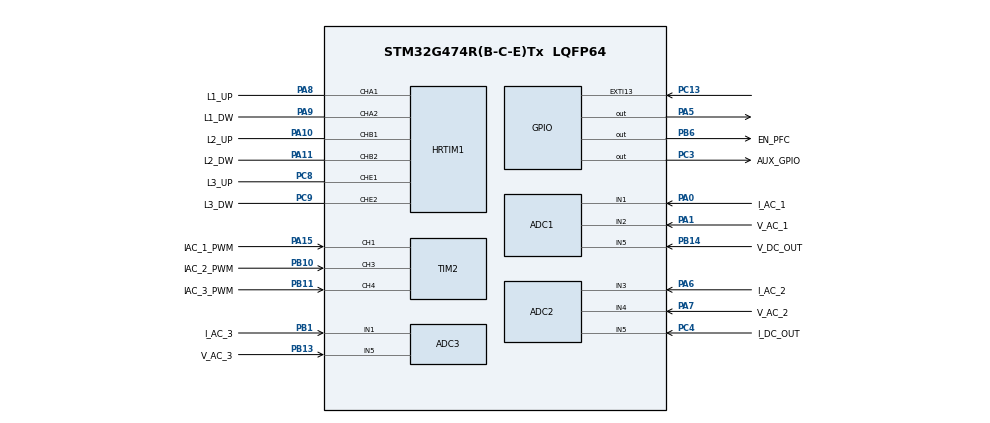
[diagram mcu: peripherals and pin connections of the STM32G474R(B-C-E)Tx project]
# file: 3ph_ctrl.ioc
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ADC1.Channel-0\#ChannelRegularConversion=ADC_CHANNEL_1
ADC1.Channel-1\#ChannelRegularConversion=ADC_CHANNEL_2
ADC1.Channel-2\#ChannelRegularConversion=ADC_CHANNEL_5
ADC1.ClockPrescaler=ADC_CLOCK_ASYNC_DIV6
ADC1.ContinuousConvMode=DISABLE
ADC1.DMAContinuousRequests=ENABLE
ADC1.EOCSelection=ADC_EOC_SEQ_CONV
ADC1.ExternalTrigConv=ADC_EXTERNALTRIG_T1_TRGO
ADC1.NbrOfConversion=3
ADC1.NbrOfConversionFlag=1
ADC1.OffsetNumber-0\#ChannelRegularConversion=ADC_OFFSET_NONE
ADC1.OffsetNumber-1\#ChannelRegularConversion=ADC_OFFSET_NONE
ADC1.OffsetNumber-2\#ChannelRegularConversion=ADC_OFFSET_NONE
ADC1.OversamplingMode=DISABLE
ADC1.Rank-0\#ChannelRegularConversion=1
ADC1.Rank-1\#ChannelRegularConversion=2
ADC1.Rank-2\#ChannelRegularConversion=3
ADC1.SamplingTime-0\#ChannelRegularConversion=ADC_SAMPLETIME_92CYCLES_5
ADC1.SamplingTime-1\#ChannelRegularConversion=ADC_SAMPLETIME_92CYCLES_5
ADC1.SamplingTime-2\#ChannelRegularConversion=ADC_SAMPLETIME_92CYCLES_5
ADC1.master=1
ADC2.Channel-0\#ChannelRegularConversion=ADC_CHANNEL_3
ADC2.Channel-1\#ChannelRegularConversion=ADC_CHANNEL_4
ADC2.Channel-2\#ChannelRegularConversion=ADC_CHANNEL_5
ADC2.ClockPrescaler=ADC_CLOCK_ASYNC_DIV6
ADC2.ContinuousConvMode=DISABLE
ADC2.DMAContinuousRequests=ENABLE
ADC2.EOCSelection=ADC_EOC_SEQ_CONV
ADC2.ExternalTrigConv=ADC_EXTERNALTRIG_T1_TRGO
ADC2.NbrOfConversion=3
ADC2.NbrOfConversionFlag=1
ADC2.OffsetNumber-0\#ChannelRegularConversion=ADC_OFFSET_NONE
ADC2.OffsetNumber-1\#ChannelRegularConversion=ADC_OFFSET_NONE
ADC2.OffsetNumber-2\#ChannelRegularConversion=ADC_OFFSET_NONE
ADC2.OversamplingMode=DISABLE
ADC2.Rank-0\#ChannelRegularConversion=1
ADC2.Rank-1\#ChannelRegularConversion=2
ADC2.Rank-2\#ChannelRegularConversion=3
ADC2.SamplingTime-0\#ChannelRegularConversion=ADC_SAMPLETIME_92CYCLES_5
ADC2.SamplingTime-1\#ChannelRegularConversion=ADC_SAMPLETIME_92CYCLES_5
ADC2.SamplingTime-2\#ChannelRegularConversion=ADC_SAMPLETIME_92CYCLES_5
ADC3.Channel-0\#ChannelRegularConversion=ADC_CHANNEL_1
ADC3.Channel-1\#ChannelRegularConversion=ADC_CHANNEL_5
ADC3.ClockPrescaler=ADC_CLOCK_ASYNC_DIV6
ADC3.ContinuousConvMode=DISABLE
ADC3.DMAContinuousRequests=ENABLE
ADC3.EOCSelection=ADC_EOC_SEQ_CONV
ADC3.ExternalTrigConv=ADC_EXTERNALTRIG_T1_TRGO
ADC3.NbrOfConversion=2
ADC3.NbrOfConversionFlag=1
ADC3.OffsetNumber-0\#ChannelRegularConversion=ADC_OFFSET_NONE
ADC3.OffsetNumber-1\#ChannelRegularConversion=ADC_OFFSET_NONE
ADC3.OversamplingMode=DISABLE
ADC3.Rank-0\#ChannelRegularConversion=1
ADC3.Rank-1\#ChannelRegularConversion=2
ADC3.SamplingTime-0\#ChannelRegularConversion=ADC_SAMPLETIME_92CYCLES_5
ADC3.SamplingTime-1\#ChannelRegularConversion=ADC_SAMPLETIME_92CYCLES_5
ADC3.master=1
Dma.ADC1.0.Direction=DMA_PERIPH_TO_MEMORY
Dma.ADC1.0.EventEnable=DISABLE
Dma.ADC1.0.Instance=DMA1_Channel1
Dma.ADC1.0.MemDataAlignment=DMA_MDATAALIGN_WORD
Dma.ADC1.0.MemInc=DMA_MINC_ENABLE
Dma.ADC1.0.Mode=DMA_CIRCULAR
Dma.ADC1.0.PeriphDataAlignment=DMA_PDATAALIGN_WORD
Dma.ADC1.0.PeriphInc=DMA_PINC_DISABLE
Dma.ADC1.0.Polarity=HAL_DMAMUX_REQ_GEN_RISING
Dma.ADC1.0.Priority=DMA_PRIORITY_HIGH
Dma.ADC1.0.RequestNumber=1
Dma.ADC1.0.SignalID=NONE
Dma.ADC1.0.SyncEnable=DISABLE
Dma.ADC1.0.SyncPolarity=HAL_DMAMUX_SYNC_NO_EVENT
Dma.ADC1.0.SyncRequestNumber=1
Dma.ADC1.0.SyncSignalID=NONE
Dma.ADC2.1.Direction=DMA_PERIPH_TO_MEMORY
Dma.ADC2.1.EventEnable=DISABLE
Dma.ADC2.1.Instance=DMA1_Channel2
Dma.ADC2.1.MemDataAlignment=DMA_MDATAALIGN_WORD
Dma.ADC2.1.MemInc=DMA_MINC_ENABLE
Dma.ADC2.1.Mode=DMA_CIRCULAR
Dma.ADC2.1.PeriphDataAlignment=DMA_PDATAALIGN_WORD
Dma.ADC2.1.PeriphInc=DMA_PINC_DISABLE
Dma.ADC2.1.Polarity=HAL_DMAMUX_REQ_GEN_RISING
Dma.ADC2.1.Priority=DMA_PRIORITY_HIGH
Dma.ADC2.1.RequestNumber=1
Dma.ADC2.1.SignalID=NONE
Dma.ADC2.1.SyncEnable=DISABLE
Dma.ADC2.1.SyncPolarity=HAL_DMAMUX_SYNC_NO_EVENT
Dma.ADC2.1.SyncRequestNumber=1
Dma.ADC2.1.SyncSignalID=NONE
Dma.ADC3.2.Direction=DMA_PERIPH_TO_MEMORY
Dma.ADC3.2.EventEnable=DISABLE
Dma.ADC3.2.Instance=DMA1_Channel3
Dma.ADC3.2.MemDataAlignment=DMA_MDATAALIGN_WORD
Dma.ADC3.2.MemInc=DMA_MINC_ENABLE
Dma.ADC3.2.Mode=DMA_CIRCULAR
Dma.ADC3.2.PeriphDataAlignment=DMA_PDATAALIGN_WORD
Dma.ADC3.2.PeriphInc=DMA_PINC_DISABLE
Dma.ADC3.2.Polarity=HAL_DMAMUX_REQ_GEN_RISING
Dma.ADC3.2.Priority=DMA_PRIORITY_HIGH
Dma.ADC3.2.RequestNumber=1
Dma.ADC3.2.SignalID=NONE
Dma.ADC3.2.SyncEnable=DISABLE
Dma.ADC3.2.SyncPolarity=HAL_DMAMUX_SYNC_NO_EVENT
Dma.ADC3.2.SyncRequestNumber=1
Dma.ADC3.2.SyncSignalID=NONE
Dma.Request0=ADC1
Dma.Request1=ADC2
Dma.Request2=ADC3
Dma.Request3=TIM2_CH1
Dma.Request4=TIM2_CH2
Dma.Request5=TIM2_CH3
Dma.Request6=TIM2_CH4
Dma.TIM2_CH1.3.Direction=DMA_PERIPH_TO_MEMORY
Dma.TIM2_CH1.3.EventEnable=DISABLE
Dma.TIM2_CH1.3.Instance=DMA1_Channel4
Dma.TIM2_CH1.3.MemDataAlignment=DMA_MDATAALIGN_WORD
Dma.TIM2_CH1.3.MemInc=DMA_MINC_ENABLE
Dma.TIM2_CH1.3.Mode=DMA_CIRCULAR
Dma.TIM2_CH1.3.PeriphDataAlignment=DMA_PDATAALIGN_WORD
Dma.TIM2_CH1.3.PeriphInc=DMA_PINC_DISABLE
Dma.TIM2_CH1.3.Polarity=HAL_DMAMUX_REQ_GEN_RISING
Dma.TIM2_CH1.3.Priority=DMA_PRIORITY_VERY_HIGH
Dma.TIM2_CH1.3.RequestNumber=1
Dma.TIM2_CH1.3.SignalID=NONE
Dma.TIM2_CH1.3.SyncEnable=DISABLE
Dma.TIM2_CH1.3.SyncPolarity=HAL_DMAMUX_SYNC_NO_EVENT
Dma.TIM2_CH1.3.SyncRequestNumber=1
Dma.TIM2_CH1.3.SyncSignalID=NONE
Dma.TIM2_CH2.4.Direction=DMA_PERIPH_TO_MEMORY
Dma.TIM2_CH2.4.EventEnable=DISABLE
Dma.TIM2_CH2.4.Instance=DMA1_Channel5
Dma.TIM2_CH2.4.MemDataAlignment=DMA_MDATAALIGN_WORD
Dma.TIM2_CH2.4.MemInc=DMA_MINC_ENABLE
Dma.TIM2_CH2.4.Mode=DMA_CIRCULAR
Dma.TIM2_CH2.4.PeriphDataAlignment=DMA_PDATAALIGN_WORD
Dma.TIM2_CH2.4.PeriphInc=DMA_PINC_DISABLE
Dma.TIM2_CH2.4.Polarity=HAL_DMAMUX_REQ_GEN_RISING
Dma.TIM2_CH2.4.Priority=DMA_PRIORITY_VERY_HIGH
Dma.TIM2_CH2.4.RequestNumber=1
Dma.TIM2_CH2.4.SignalID=NONE
Dma.TIM2_CH2.4.SyncEnable=DISABLE
Dma.TIM2_CH2.4.SyncPolarity=HAL_DMAMUX_SYNC_NO_EVENT
Dma.TIM2_CH2.4.SyncRequestNumber=1
Dma.TIM2_CH2.4.SyncSignalID=NONE
Dma.TIM2_CH3.5.Direction=DMA_PERIPH_TO_MEMORY
Dma.TIM2_CH3.5.EventEnable=DISABLE
Dma.TIM2_CH3.5.Instance=DMA1_Channel6
Dma.TIM2_CH3.5.MemDataAlignment=DMA_MDATAALIGN_WORD
Dma.TIM2_CH3.5.MemInc=DMA_MINC_ENABLE
Dma.TIM2_CH3.5.Mode=DMA_CIRCULAR
Dma.TIM2_CH3.5.PeriphDataAlignment=DMA_PDATAALIGN_WORD
Dma.TIM2_CH3.5.PeriphInc=DMA_PINC_DISABLE
Dma.TIM2_CH3.5.Polarity=HAL_DMAMUX_REQ_GEN_RISING
Dma.TIM2_CH3.5.Priority=DMA_PRIORITY_VERY_HIGH
Dma.TIM2_CH3.5.RequestNumber=1
Dma.TIM2_CH3.5.SignalID=NONE
Dma.TIM2_CH3.5.SyncEnable=DISABLE
Dma.TIM2_CH3.5.SyncPolarity=HAL_DMAMUX_SYNC_NO_EVENT
Dma.TIM2_CH3.5.SyncRequestNumber=1
Dma.TIM2_CH3.5.SyncSignalID=NONE
Dma.TIM2_CH4.6.Direction=DMA_PERIPH_TO_MEMORY
Dma.TIM2_CH4.6.EventEnable=DISABLE
Dma.TIM2_CH4.6.Instance=DMA1_Channel7
Dma.TIM2_CH4.6.MemDataAlignment=DMA_MDATAALIGN_WORD
Dma.TIM2_CH4.6.MemInc=DMA_MINC_ENABLE
Dma.TIM2_CH4.6.Mode=DMA_CIRCULAR
Dma.TIM2_CH4.6.PeriphDataAlignment=DMA_PDATAALIGN_WORD
Dma.TIM2_CH4.6.PeriphInc=DMA_PINC_DISABLE
Dma.TIM2_CH4.6.Polarity=HAL_DMAMUX_REQ_GEN_RISING
Dma.TIM2_CH4.6.Priority=DMA_PRIORITY_VERY_HIGH
Dma.TIM2_CH4.6.RequestNumber=1
Dma.TIM2_CH4.6.SignalID=NONE
Dma.TIM2_CH4.6.SyncEnable=DISABLE
Dma.TIM2_CH4.6.SyncPolarity=HAL_DMAMUX_SYNC_NO_EVENT
Dma.TIM2_CH4.6.SyncRequestNumber=1
Dma.TIM2_CH4.6.SyncSignalID=NONE
HRTIM1.CompareUnit1-MasterTimer=HRTIM_COMPAREUNIT_1
HRTIM1.CompareUnit1-Output_TA1TA2=HRTIM_COMPAREUNIT_1
HRTIM1.CompareUnit1-Output_TB1TB2=HRTIM_COMPAREUNIT_1
HRTIM1.CompareUnit1-Output_TE1TE2=HRTIM_COMPAREUNIT_1
HRTIM1.CompareValue1-Output_TA1TA2=30000
HRTIM1.CompareValue1-Output_TB1TB2=10000
HRTIM1.CompareValue1-Output_TE1TE2=20000
HRTIM1.DeadTimeInsertion-Output_TA1TA2=HRTIM_TIMDEADTIMEINSERTION_ENABLED
HRTIM1.DeadTimeInsertion-Output_TB1TB2=HRTIM_TIMDEADTIMEINSERTION_ENABLED
HRTIM1.DeadTimeInsertion-Output_TE1TE2=HRTIM_TIMDEADTIMEINSERTION_ENABLED
HRTIM1.FallingValue-Output_TA1TA2=274
HRTIM1.FallingValue-Output_TB1TB2=274
HRTIM1.FallingValue-Output_TE1TE2=320
HRTIM1.GreaterCMP1_TA=HRTIM_TIMERGTCMP1_GREATER
HRTIM1.GreaterCMP1_TB=HRTIM_TIMERGTCMP1_GREATER
HRTIM1.GreaterCMP1_TE=HRTIM_TIMERGTCMP1_GREATER
HRTIM1.NumberResetSource1-Output_TA1TA2=1
HRTIM1.NumberResetSource1-Output_TB1TB2=1
HRTIM1.NumberResetSource1-Output_TE1TE2=1
HRTIM1.NumberResetSource2_TA=1
HRTIM1.NumberResetTrigger-Output_TA1TA2=1
HRTIM1.NumberResetTrigger-Output_TB1TB2=1
HRTIM1.NumberResetTrigger-Output_TE1TE2=1
HRTIM1.NumberSetSource1-Output_TA1TA2=1
HRTIM1.NumberSetSource1-Output_TB1TB2=1
HRTIM1.NumberSetSource1-Output_TE1TE2=1
HRTIM1.NumberSetSource2_TA=1
HRTIM1.NumberUpdateTrigger-Output_TA1TA2=0
HRTIM1.NumberUpdateTrigger-Output_TB1TB2=1
HRTIM1.Periode_MASTER=41846
HRTIM1.Periode_TA=41846
HRTIM1.Periode_TB=41846
HRTIM1.Periode_TE=41846
HRTIM1.PreloadEnable-Output_TA1TA2=HRTIM_PRELOAD_ENABLED
HRTIM1.PreloadEnable-Output_TB1TB2=HRTIM_PRELOAD_ENABLED
HRTIM1.PreloadEnable-Output_TE1TE2=HRTIM_PRELOAD_ENABLED
HRTIM1.PrescalerRatio_MASTER=HRTIM_PRESCALERRATIO_MUL16
HRTIM1.PrescalerRatio_TA=HRTIM_PRESCALERRATIO_MUL32
HRTIM1.PrescalerRatio_TB=HRTIM_PRESCALERRATIO_MUL32
HRTIM1.PrescalerRatio_TE=HRTIM_PRESCALERRATIO_MUL32
HRTIM1.RepetitionUpdate-Output_TA1TA2=HRTIM_UPDATEONREPETITION_ENABLED
HRTIM1.RepetitionUpdate-Output_TB1TB2=HRTIM_UPDATEONREPETITION_ENABLED
HRTIM1.RepetitionUpdate-Output_TE1TE2=HRTIM_UPDATEONREPETITION_ENABLED
HRTIM1.ResetOutput1_Source1-Output_TA1TA2=HRTIM_OUTPUTRESET_TIMCMP1
HRTIM1.ResetOutput1_Source1-Output_TB1TB2=HRTIM_OUTPUTRESET_TIMCMP1
HRTIM1.ResetOutput1_Source1-Output_TE1TE2=HRTIM_OUTPUTRESET_TIMCMP1
HRTIM1.ResetOutput2_Source1-Output_TA1TA2=HRTIM_OUTPUTRESET_TIMCMP1
HRTIM1.ResetTrigger1-Output_TA1TA2=HRTIM_TIMRESETTRIGGER_MASTER_CMP1
HRTIM1.ResetTrigger1-Output_TB1TB2=HRTIM_TIMRESETTRIGGER_MASTER_CMP1
HRTIM1.ResetTrigger1-Output_TE1TE2=HRTIM_TIMRESETTRIGGER_MASTER_CMP1
HRTIM1.RisingValue-Output_TA1TA2=320
HRTIM1.RisingValue-Output_TB1TB2=320
HRTIM1.RisingValue-Output_TE1TE2=274
HRTIM1.SetOutput1_Source1-Output_TA1TA2=HRTIM_OUTPUTSET_TIMCMP1
HRTIM1.SetOutput1_Source1-Output_TB1TB2=HRTIM_OUTPUTSET_TIMCMP1
HRTIM1.SetOutput1_Source1-Output_TE1TE2=HRTIM_OUTPUTSET_TIMCMP1
HRTIM1.SetOutput2_Source1-Output_TA1TA2=HRTIM_OUTPUTSET_TIMCMP1
HRTIM1.UpDownMode-Output_TA1TA2=HRTIM_TIMERUPDOWNMODE_UPDOWN
HRTIM1.UpDownMode-Output_TB1TB2=HRTIM_TIMERUPDOWNMODE_UPDOWN
HRTIM1.UpDownMode-Output_TE1TE2=HRTIM_TIMERUPDOWNMODE_UPDOWN
HRTIM1.UpdateTrigger1-Output_TB1TB2=HRTIM_TIMUPDATETRIGGER_MASTER
Mcu.Family=STM32G4
Mcu.Name=STM32G474R(B-C-E)Tx
Mcu.Package=LQFP64
NUCLEO-G474RE.BUTTON=1
NUCLEO-G474RE.LD2=true
NUCLEO-G474RE.VCP=true
NVIC.DMA1_Channel1_IRQn=true\:0\:0\:false\:false\:true\:false\:true\:true
NVIC.DMA1_Channel2_IRQn=true\:0\:0\:false\:false\:true\:false\:true\:true
NVIC.DMA1_Channel3_IRQn=true\:0\:0\:false\:false\:true\:false\:true\:true
NVIC.DMA1_Channel4_IRQn=true\:0\:0\:false\:false\:true\:false\:true\:true
NVIC.DMA1_Channel5_IRQn=true\:0\:0\:false\:false\:true\:false\:true\:true
NVIC.DMA1_Channel6_IRQn=true\:0\:0\:false\:false\:true\:false\:true\:true
NVIC.DMA1_Channel7_IRQn=true\:0\:0\:false\:false\:true\:false\:true\:true
NVIC.EXTI15_10_IRQn=true\:0\:0\:false\:false\:true\:true\:true\:true
NVIC.PriorityGroup=NVIC_PRIORITYGROUP_4
NVIC.TIM1_UP_TIM16_IRQn=true\:0\:0\:false\:false\:true\:true\:true\:true
PA0.GPIO_Label=I_AC_1
PA0.Mode=IN1-Single-Ended
PA0.Signal=ADC1_IN1
PA1.GPIO_Label=V_AC_1
PA1.Mode=IN2-Single-Ended
PA1.Signal=ADC1_IN2
PA10.GPIO_Label=L2_UP
PA10.Mode=Output_TB1TB2
PA10.Signal=HRTIM1_CHB1
PA11.GPIO_Label=L2_DW
PA11.Mode=Output_TB1TB2
PA11.Signal=HRTIM1_CHB2
PA13.GPIO_Label=T_SWDIO
PA13.Signal=SYS_JTMS-SWDIO
PA14.GPIO_Label=T_SWCLK
PA14.Signal=SYS_JTCK-SWCLK
PA15.GPIO_Label=IAC_1_PWM
PA15.GPIO_Speed=GPIO_SPEED_FREQ_HIGH
PA15.Signal=S_TIM2_CH1
PA2.Signal=LPUART1_TX
PA3.Signal=LPUART1_RX
PA5.Signal=GPIO_Output
PA6.GPIO_Label=I_AC_2
PA6.Mode=IN3-Single-Ended
PA6.Signal=ADC2_IN3
PA7.GPIO_Label=V_AC_2
PA7.Mode=IN4-Single-Ended
PA7.Signal=ADC2_IN4
PA8.GPIO_Label=L1_UP
PA8.Mode=Output_TA1TA2
PA8.Signal=HRTIM1_CHA1
PA9.GPIO_Label=L1_DW
PA9.Mode=Output_TA1TA2
PA9.Signal=HRTIM1_CHA2
PB1.GPIO_Label=I_AC_3
PB1.Mode=IN1-Single-Ended
PB1.Signal=ADC3_IN1
PB10.GPIO_Label=IAC_2_PWM
PB10.GPIO_Speed=GPIO_SPEED_FREQ_HIGH
PB10.Signal=S_TIM2_CH3
PB11.GPIO_Label=IAC_3_PWM
PB11.GPIO_Speed=GPIO_SPEED_FREQ_HIGH
PB11.Signal=S_TIM2_CH4
PB13.GPIO_Label=V_AC_3
PB13.Mode=IN5-Single-Ended
PB13.Signal=ADC3_IN5
PB14.GPIO_Label=V_DC_OUT
PB14.Mode=IN5-Single-Ended
PB14.Signal=ADC1_IN5
PB3.GPIO_Label=T_SWO
PB3.Signal=SYS_JTDO-SWO
PB6.GPIO_Label=EN_PFC
PB6.Signal=GPIO_Output
PC13.Signal=GPXTI13
PC14-OSC32_IN.GPIO_Label=RCC_OSC32_IN
PC14-OSC32_IN.Signal=RCC_OSC32_IN
PC15-OSC32_OUT.GPIO_Label=RCC_OSC32_OUT
PC15-OSC32_OUT.Signal=RCC_OSC32_OUT
PC3.GPIO_Label=AUX_GPIO
PC3.GPIO_Speed=GPIO_SPEED_FREQ_VERY_HIGH
PC3.Signal=GPIO_Output
PC4.GPIO_Label=I_DC_OUT
PC4.Mode=IN5-Single-Ended
PC4.Signal=ADC2_IN5
PC8.GPIO_Label=L3_UP
PC8.Mode=Output_TE1TE2
PC8.Signal=HRTIM1_CHE1
PC9.GPIO_Label=L3_DW
PC9.Mode=Output_TE1TE2
PC9.Signal=HRTIM1_CHE2
PF0-OSC_IN.GPIO_Label=RCC_OSC_IN
PF0-OSC_IN.Signal=RCC_OSC_IN
PF1-OSC_OUT.GPIO_Label=RCC_OSC_OUT
PF1-OSC_OUT.Signal=RCC_OSC_OUT
ProjectManager.HeapSize=0x200
ProjectManager.StackSize=0x400
ProjectManager.TargetToolchain=CMake
RCC.ADC12Freq_Value=170000000
RCC.ADC345Freq_Value=170000000
RCC.AHBFreq_Value=170000000
RCC.APB1Freq_Value=170000000
RCC.APB1TimFreq_Value=170000000
RCC.APB2Freq_Value=170000000
RCC.APB2TimFreq_Value=170000000
RCC.CortexFreq_Value=170000000
RCC.EXTERNAL_CLOCK_VALUE=12288000
RCC.HCLKFreq_Value=170000000
RCC.HSE_VALUE=24000000
RCC.HSI48_VALUE=48000000
RCC.HSI_VALUE=16000000
RCC.LSE_VALUE=32768
RCC.PLLM=RCC_PLLM_DIV4
RCC.PLLN=85
RCC.RTCClockSelection=RCC_RTCCLKSOURCE_LSE
RCC.SYSCLKFreq_VALUE=170000000
RCC.SYSCLKSource=RCC_SYSCLKSOURCE_PLLCLK
RCC.USBFreq_Value=170000000
RCC.VCOOutputFreq_Value=340000000
SH.S_TIM2_CH1.0=TIM2_CH1,Input_Capture1_from_TI1
SH.S_TIM2_CH1.1=TIM2_CH1,TriggerSource_TI1FP1
SH.S_TIM2_CH3.0=TIM2_CH3,Input_Capture3_from_TI3
SH.S_TIM2_CH4.0=TIM2_CH4,Input_Capture4_from_TI4
TIM1.PeriodNoDither=21250
TIM1.TIM_MasterOutputTrigger=TIM_TRGO_UPDATE
TIM1.TIM_MasterOutputTrigger2=TIM_TRGO2_UPDATE
TIM1.TIM_MasterSlaveMode=TIM_MASTERSLAVEMODE_DISABLE
TIM2.Channel-Input_Capture1_from_TI1=TIM_CHANNEL_1
TIM2.Channel-Input_Capture2_from_TI1_63=TIM_CHANNEL_2
TIM2.Channel-Input_Capture3_from_TI3=TIM_CHANNEL_3
TIM2.Channel-Input_Capture4_from_TI4=TIM_CHANNEL_4
TIM2.ICFilter_CH1=10
TIM2.ICFilter_CH3=10
TIM2.ICFilter_CH4=10
TIM2.ICPolarity_CH2=TIM_INPUTCHANNELPOLARITY_FALLING
TIM2.ICPolarity_CH3=TIM_INPUTCHANNELPOLARITY_FALLING
TIM2.ICPolarity_CH4=TIM_INPUTCHANNELPOLARITY_FALLING
VP_FMAC_VS_FMAC.Mode=FMAC_Activate
VP_HRTIM1_VS_hrtimMasterTimerNoOutput.Mode=MasterTimer
VP_NUCLEO-G474RE_VS_BSP_COMMON.Mode=COMMON
VP_SYS_VS_DBSignals.Mode=DisableDeadBatterySignals
VP_TIM1_VS_ClockSourceINT.Mode=Internal
VP_TIM2_VS_ClockSourceINT.Mode=Internal
VP_TIM2_VS_ControllerModeReset.Mode=Reset Mode
VP_TIM2_VS_indirect_ch1.Mode=Input_Capture2_from_TI1_63
board=NUCLEO-G474RE

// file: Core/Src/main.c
/* USER CODE BEGIN Header */
/**
 ******************************************************************************
 * @file           : main.c
 * @brief          : Main program body
 ******************************************************************************
 * @attention
 *
 * Copyright (c) 2025 STMicroelectronics.
 * All rights reserved.
 *
 * This software is licensed under terms that can be found in the LICENSE file
 * in the root directory of this software component.
 * If no LICENSE file comes with this software, it is provided AS-IS.
 *
 ******************************************************************************
 */
/* USER CODE END Header */
#include "main.h"

/* USER CODE BEGIN PD */
uint32_t adc1_data[18], adc2_data[18], adc3_data[12], i_ac[4];

/* USER CODE END PD */

COM_InitTypeDef BspCOMInit;

void SystemClock_Config(void);
static void MX_GPIO_Init(void);
static void MX_DMA_Init(void);
static void MX_ADC1_Init(void);
static void MX_ADC2_Init(void);
static void MX_ADC3_Init(void);
static void MX_FMAC_Init(void);
static void MX_TIM1_Init(void);
static void MX_HRTIM1_Init(void);
static void MX_TIM2_Init(void);

int main(void)
{

  /* MCU Configuration--------------------------------------------------------*/

  /* Reset of all peripherals, Initializes the Flash interface and the Systick. */
  HAL_Init();

  /* Configure the system clock */
  SystemClock_Config();

  /* Initialize all configured peripherals */
  MX_GPIO_Init();
  MX_DMA_Init();
  MX_ADC1_Init();
  MX_ADC2_Init();
  MX_ADC3_Init();
  MX_FMAC_Init();
  MX_TIM1_Init();
  MX_HRTIM1_Init();
  MX_TIM2_Init();

  /* Initialize led */
  BSP_LED_Init(LED_GREEN);

  /* Initialize USER push-button, will be used to trigger an interrupt each time it's pressed.*/
  BSP_PB_Init(BUTTON_USER, BUTTON_MODE_EXTI);

  /* Initialize COM1 port (115200, 8 bits (7-bit data + 1 stop bit), no parity */
  BspCOMInit.BaudRate   = 115200;
  BspCOMInit.WordLength = COM_WORDLENGTH_8B;
  BspCOMInit.StopBits   = COM_STOPBITS_1;
  BspCOMInit.Parity     = COM_PARITY_NONE;
  BspCOMInit.HwFlowCtl  = COM_HWCONTROL_NONE;
  if (BSP_COM_Init(COM1, &BspCOMInit) != BSP_ERROR_NONE)
  {
    Error_Handler();
  }

  /* Infinite loop */
  /* USER CODE BEGIN WHILE */
  __disable_irq();

  LL_ADC_ClearFlag_OVR(ADC1);
  LL_ADC_ClearFlag_OVR(ADC2);
  LL_ADC_ClearFlag_OVR(ADC3);
  LL_ADC_Enable(ADC1);
  LL_ADC_Enable(ADC2);
  LL_ADC_Enable(ADC3);
  LL_ADC_REG_StartConversion(ADC1);
  LL_ADC_REG_StartConversion(ADC2);
  LL_ADC_REG_StartConversion(ADC3);
  LL_TIM_CC_EnableChannel(TIM2, LL_TIM_CHANNEL_CH1);
  LL_TIM_CC_EnableChannel(TIM2, LL_TIM_CHANNEL_CH2);
  LL_TIM_CC_EnableChannel(TIM2, LL_TIM_CHANNEL_CH3);
  LL_TIM_CC_EnableChannel(TIM2, LL_TIM_CHANNEL_CH4);
  LL_TIM_EnableCounter(TIM2);
  /*HRTIM*/

  __enable_irq();
  while (1) {

    /* USER CODE END WHILE */

  }
}

void SystemClock_Config(void)
{
  LL_FLASH_SetLatency(LL_FLASH_LATENCY_4);
  while(LL_FLASH_GetLatency() != LL_FLASH_LATENCY_4)
  {
  }
  LL_PWR_EnableRange1BoostMode();
  LL_RCC_HSI_Enable();
   /* Wait till HSI is ready */
  while(LL_RCC_HSI_IsReady() != 1)
  {
  }

  LL_RCC_HSI_SetCalibTrimming(64);
  LL_RCC_PLL_ConfigDomain_SYS(LL_RCC_PLLSOURCE_HSI, LL_RCC_PLLM_DIV_4, 85, LL_RCC_PLLR_DIV_2);
  LL_RCC_PLL_EnableDomain_SYS();
  LL_RCC_PLL_Enable();
   /* Wait till PLL is ready */
  while(LL_RCC_PLL_IsReady() != 1)
  {
  }

  LL_RCC_SetSysClkSource(LL_RCC_SYS_CLKSOURCE_PLL);
  LL_RCC_SetAHBPrescaler(LL_RCC_SYSCLK_DIV_2);
   /* Wait till System clock is ready */
  while(LL_RCC_GetSysClkSource() != LL_RCC_SYS_CLKSOURCE_STATUS_PLL)
  {
  }

  /* Insure 1us transition state at intermediate medium speed clock*/
  for (__IO uint32_t i = (170 >> 1); i !=0; i--);

  /* Set AHB prescaler*/
  LL_RCC_SetAHBPrescaler(LL_RCC_SYSCLK_DIV_1);
  LL_RCC_SetAPB1Prescaler(LL_RCC_APB1_DIV_1);
  LL_RCC_SetAPB2Prescaler(LL_RCC_APB2_DIV_1);
  LL_SetSystemCoreClock(170000000);

   /* Update the time base */
  if (HAL_InitTick (TICK_INT_PRIORITY) != HAL_OK)
  {
    Error_Handler();
  }
}

static void MX_ADC1_Init(void)
{

  LL_ADC_InitTypeDef ADC_InitStruct = {0};
  LL_ADC_REG_InitTypeDef ADC_REG_InitStruct = {0};
  LL_ADC_CommonInitTypeDef ADC_CommonInitStruct = {0};

  LL_GPIO_InitTypeDef GPIO_InitStruct = {0};

  LL_RCC_SetADCClockSource(LL_RCC_ADC12_CLKSOURCE_SYSCLK);

  /* Peripheral clock enable */
  LL_AHB2_GRP1_EnableClock(LL_AHB2_GRP1_PERIPH_ADC12);

  LL_AHB2_GRP1_EnableClock(LL_AHB2_GRP1_PERIPH_GPIOA);
  LL_AHB2_GRP1_EnableClock(LL_AHB2_GRP1_PERIPH_GPIOB);
  /**ADC1 GPIO Configuration
  PA0   ------> ADC1_IN1
  PA1   ------> ADC1_IN2
  PB14   ------> ADC1_IN5
  */
  GPIO_InitStruct.Pin = I_AC_1_Pin;
  GPIO_InitStruct.Mode = LL_GPIO_MODE_ANALOG;
  GPIO_InitStruct.Pull = LL_GPIO_PULL_NO;
  LL_GPIO_Init(I_AC_1_GPIO_Port, &GPIO_InitStruct);

  GPIO_InitStruct.Pin = V_AC_1_Pin;
  GPIO_InitStruct.Mode = LL_GPIO_MODE_ANALOG;
  GPIO_InitStruct.Pull = LL_GPIO_PULL_NO;
  LL_GPIO_Init(V_AC_1_GPIO_Port, &GPIO_InitStruct);

  GPIO_InitStruct.Pin = V_DC_OUT_Pin;
  GPIO_InitStruct.Mode = LL_GPIO_MODE_ANALOG;
  GPIO_InitStruct.Pull = LL_GPIO_PULL_NO;
  LL_GPIO_Init(V_DC_OUT_GPIO_Port, &GPIO_InitStruct);

  /* ADC1 DMA Init */

  /* ADC1 Init */
  LL_DMA_SetPeriphRequest(DMA1, LL_DMA_CHANNEL_1, LL_DMAMUX_REQ_ADC1);

  LL_DMA_SetDataTransferDirection(DMA1, LL_DMA_CHANNEL_1, LL_DMA_DIRECTION_PERIPH_TO_MEMORY);

  LL_DMA_SetChannelPriorityLevel(DMA1, LL_DMA_CHANNEL_1, LL_DMA_PRIORITY_HIGH);

  LL_DMA_SetMode(DMA1, LL_DMA_CHANNEL_1, LL_DMA_MODE_CIRCULAR);

  LL_DMA_SetPeriphIncMode(DMA1, LL_DMA_CHANNEL_1, LL_DMA_PERIPH_NOINCREMENT);

  LL_DMA_SetMemoryIncMode(DMA1, LL_DMA_CHANNEL_1, LL_DMA_MEMORY_INCREMENT);

  LL_DMA_SetPeriphSize(DMA1, LL_DMA_CHANNEL_1, LL_DMA_PDATAALIGN_WORD);

  LL_DMA_SetMemorySize(DMA1, LL_DMA_CHANNEL_1, LL_DMA_MDATAALIGN_WORD);

  /** Common config
  */
  ADC_InitStruct.Resolution = LL_ADC_RESOLUTION_12B;
  ADC_InitStruct.DataAlignment = LL_ADC_DATA_ALIGN_RIGHT;
  ADC_InitStruct.LowPowerMode = LL_ADC_LP_MODE_NONE;
  LL_ADC_Init(ADC1, &ADC_InitStruct);
  ADC_REG_InitStruct.TriggerSource = LL_ADC_REG_TRIG_EXT_TIM1_TRGO;
  ADC_REG_InitStruct.SequencerLength = LL_ADC_REG_SEQ_SCAN_ENABLE_3RANKS;
  ADC_REG_InitStruct.SequencerDiscont = LL_ADC_REG_SEQ_DISCONT_DISABLE;
  ADC_REG_InitStruct.ContinuousMode = LL_ADC_REG_CONV_SINGLE;
  ADC_REG_InitStruct.DMATransfer = LL_ADC_REG_DMA_TRANSFER_UNLIMITED;
  ADC_REG_InitStruct.Overrun = LL_ADC_REG_OVR_DATA_PRESERVED;
  LL_ADC_REG_Init(ADC1, &ADC_REG_InitStruct);
  LL_ADC_SetGainCompensation(ADC1, 0);
  LL_ADC_SetOverSamplingScope(ADC1, LL_ADC_OVS_DISABLE);
  ADC_CommonInitStruct.CommonClock = LL_ADC_CLOCK_ASYNC_DIV6;
  ADC_CommonInitStruct.Multimode = LL_ADC_MULTI_INDEPENDENT;
  LL_ADC_CommonInit(__LL_ADC_COMMON_INSTANCE(ADC1), &ADC_CommonInitStruct);
  LL_ADC_REG_SetTriggerEdge(ADC1, LL_ADC_REG_TRIG_EXT_RISING);

  /* Disable ADC deep power down (enabled by default after reset state) */
  LL_ADC_DisableDeepPowerDown(ADC1);
  /* Enable ADC internal voltage regulator */
  LL_ADC_EnableInternalRegulator(ADC1);
  /* Delay for ADC internal voltage regulator stabilization. */
  /* Compute number of CPU cycles to wait for, from delay in us. */
  /* Note: Variable divided by 2 to compensate partially */
  /* CPU processing cycles (depends on compilation optimization). */
  /* Note: If system core clock frequency is below 200kHz, wait time */
  /* is only a few CPU processing cycles. */
  uint32_t wait_loop_index;
  wait_loop_index = ((LL_ADC_DELAY_INTERNAL_REGUL_STAB_US * (SystemCoreClock / (100000 * 2))) / 10);
  while(wait_loop_index != 0)
  {
    wait_loop_index--;
  }

  /** Configure Regular Channel
  */
  LL_ADC_REG_SetSequencerRanks(ADC1, LL_ADC_REG_RANK_1, LL_ADC_CHANNEL_1);
  LL_ADC_SetChannelSamplingTime(ADC1, LL_ADC_CHANNEL_1, LL_ADC_SAMPLINGTIME_92CYCLES_5);
  LL_ADC_SetChannelSingleDiff(ADC1, LL_ADC_CHANNEL_1, LL_ADC_SINGLE_ENDED);

  /** Configure Regular Channel
  */
  LL_ADC_REG_SetSequencerRanks(ADC1, LL_ADC_REG_RANK_2, LL_ADC_CHANNEL_2);
  LL_ADC_SetChannelSamplingTime(ADC1, LL_ADC_CHANNEL_2, LL_ADC_SAMPLINGTIME_92CYCLES_5);
  LL_ADC_SetChannelSingleDiff(ADC1, LL_ADC_CHANNEL_2, LL_ADC_SINGLE_ENDED);

  /** Configure Regular Channel
  */
  LL_ADC_REG_SetSequencerRanks(ADC1, LL_ADC_REG_RANK_3, LL_ADC_CHANNEL_5);
  LL_ADC_SetChannelSamplingTime(ADC1, LL_ADC_CHANNEL_5, LL_ADC_SAMPLINGTIME_92CYCLES_5);
  LL_ADC_SetChannelSingleDiff(ADC1, LL_ADC_CHANNEL_5, LL_ADC_SINGLE_ENDED);
  /* USER CODE BEGIN ADC1_Init 2 */
  LL_DMA_ConfigAddresses(
      DMA1, LL_DMA_CHANNEL_1,
      LL_ADC_DMA_GetRegAddr(ADC1, LL_ADC_DMA_REG_REGULAR_DATA),
      (uint32_t)&adc1_data[0], LL_DMA_DIRECTION_PERIPH_TO_MEMORY);
  LL_DMA_SetDataLength(DMA1, LL_DMA_CHANNEL_1, (uint32_t)NUM_TAPS * 3);
  // LL_DMA_EnableIT_TC(DMA1, LL_DMA_CHANNEL_1);
  LL_DMA_EnableChannel(DMA1, LL_DMA_CHANNEL_1);
  /* USER CODE END ADC1_Init 2 */

}

static void MX_ADC2_Init(void)
{

  LL_ADC_InitTypeDef ADC_InitStruct = {0};
  LL_ADC_REG_InitTypeDef ADC_REG_InitStruct = {0};

  LL_GPIO_InitTypeDef GPIO_InitStruct = {0};

  LL_RCC_SetADCClockSource(LL_RCC_ADC12_CLKSOURCE_SYSCLK);

  /* Peripheral clock enable */
  LL_AHB2_GRP1_EnableClock(LL_AHB2_GRP1_PERIPH_ADC12);

  LL_AHB2_GRP1_EnableClock(LL_AHB2_GRP1_PERIPH_GPIOA);
  LL_AHB2_GRP1_EnableClock(LL_AHB2_GRP1_PERIPH_GPIOC);
  /**ADC2 GPIO Configuration
  PA6   ------> ADC2_IN3
  PA7   ------> ADC2_IN4
  PC4   ------> ADC2_IN5
  */
  GPIO_InitStruct.Pin = I_AC_2_Pin;
  GPIO_InitStruct.Mode = LL_GPIO_MODE_ANALOG;
  GPIO_InitStruct.Pull = LL_GPIO_PULL_NO;
  LL_GPIO_Init(I_AC_2_GPIO_Port, &GPIO_InitStruct);

  GPIO_InitStruct.Pin = V_AC_2_Pin;
  GPIO_InitStruct.Mode = LL_GPIO_MODE_ANALOG;
  GPIO_InitStruct.Pull = LL_GPIO_PULL_NO;
  LL_GPIO_Init(V_AC_2_GPIO_Port, &GPIO_InitStruct);

  GPIO_InitStruct.Pin = I_DC_OUT_Pin;
  GPIO_InitStruct.Mode = LL_GPIO_MODE_ANALOG;
  GPIO_InitStruct.Pull = LL_GPIO_PULL_NO;
  LL_GPIO_Init(I_DC_OUT_GPIO_Port, &GPIO_InitStruct);

  /* ADC2 DMA Init */

  /* ADC2 Init */
  LL_DMA_SetPeriphRequest(DMA1, LL_DMA_CHANNEL_2, LL_DMAMUX_REQ_ADC2);

  LL_DMA_SetDataTransferDirection(DMA1, LL_DMA_CHANNEL_2, LL_DMA_DIRECTION_PERIPH_TO_MEMORY);

  LL_DMA_SetChannelPriorityLevel(DMA1, LL_DMA_CHANNEL_2, LL_DMA_PRIORITY_HIGH);

  LL_DMA_SetMode(DMA1, LL_DMA_CHANNEL_2, LL_DMA_MODE_CIRCULAR);

  LL_DMA_SetPeriphIncMode(DMA1, LL_DMA_CHANNEL_2, LL_DMA_PERIPH_NOINCREMENT);

  LL_DMA_SetMemoryIncMode(DMA1, LL_DMA_CHANNEL_2, LL_DMA_MEMORY_INCREMENT);

  LL_DMA_SetPeriphSize(DMA1, LL_DMA_CHANNEL_2, LL_DMA_PDATAALIGN_WORD);

  LL_DMA_SetMemorySize(DMA1, LL_DMA_CHANNEL_2, LL_DMA_MDATAALIGN_WORD);

  /** Common config
  */
  ADC_InitStruct.Resolution = LL_ADC_RESOLUTION_12B;
  ADC_InitStruct.DataAlignment = LL_ADC_DATA_ALIGN_RIGHT;
  ADC_InitStruct.LowPowerMode = LL_ADC_LP_MODE_NONE;
  LL_ADC_Init(ADC2, &ADC_InitStruct);
  ADC_REG_InitStruct.TriggerSource = LL_ADC_REG_TRIG_EXT_TIM1_TRGO;
  ADC_REG_InitStruct.SequencerLength = LL_ADC_REG_SEQ_SCAN_ENABLE_3RANKS;
  ADC_REG_InitStruct.SequencerDiscont = LL_ADC_REG_SEQ_DISCONT_DISABLE;
  ADC_REG_InitStruct.ContinuousMode = LL_ADC_REG_CONV_SINGLE;
  ADC_REG_InitStruct.DMATransfer = LL_ADC_REG_DMA_TRANSFER_UNLIMITED;
  ADC_REG_InitStruct.Overrun = LL_ADC_REG_OVR_DATA_PRESERVED;
  LL_ADC_REG_Init(ADC2, &ADC_REG_InitStruct);
  LL_ADC_SetGainCompensation(ADC2, 0);
  LL_ADC_SetOverSamplingScope(ADC2, LL_ADC_OVS_DISABLE);
  LL_ADC_REG_SetTriggerEdge(ADC2, LL_ADC_REG_TRIG_EXT_RISING);

  /* Disable ADC deep power down (enabled by default after reset state) */
  LL_ADC_DisableDeepPowerDown(ADC2);
  /* Enable ADC internal voltage regulator */
  LL_ADC_EnableInternalRegulator(ADC2);
  /* Delay for ADC internal voltage regulator stabilization. */
  /* Compute number of CPU cycles to wait for, from delay in us. */
  /* Note: Variable divided by 2 to compensate partially */
  /* CPU processing cycles (depends on compilation optimization). */
  /* Note: If system core clock frequency is below 200kHz, wait time */
  /* is only a few CPU processing cycles. */
  uint32_t wait_loop_index;
  wait_loop_index = ((LL_ADC_DELAY_INTERNAL_REGUL_STAB_US * (SystemCoreClock / (100000 * 2))) / 10);
  while(wait_loop_index != 0)
  {
    wait_loop_index--;
  }

  /** Configure Regular Channel
  */
  LL_ADC_REG_SetSequencerRanks(ADC2, LL_ADC_REG_RANK_1, LL_ADC_CHANNEL_3);
  LL_ADC_SetChannelSamplingTime(ADC2, LL_ADC_CHANNEL_3, LL_ADC_SAMPLINGTIME_92CYCLES_5);
  LL_ADC_SetChannelSingleDiff(ADC2, LL_ADC_CHANNEL_3, LL_ADC_SINGLE_ENDED);

  /** Configure Regular Channel
  */
  LL_ADC_REG_SetSequencerRanks(ADC2, LL_ADC_REG_RANK_2, LL_ADC_CHANNEL_4);
  LL_ADC_SetChannelSamplingTime(ADC2, LL_ADC_CHANNEL_4, LL_ADC_SAMPLINGTIME_92CYCLES_5);
  LL_ADC_SetChannelSingleDiff(ADC2, LL_ADC_CHANNEL_4, LL_ADC_SINGLE_ENDED);

  /** Configure Regular Channel
  */
  LL_ADC_REG_SetSequencerRanks(ADC2, LL_ADC_REG_RANK_3, LL_ADC_CHANNEL_5);
  LL_ADC_SetChannelSamplingTime(ADC2, LL_ADC_CHANNEL_5, LL_ADC_SAMPLINGTIME_92CYCLES_5);
  LL_ADC_SetChannelSingleDiff(ADC2, LL_ADC_CHANNEL_5, LL_ADC_SINGLE_ENDED);
  /* USER CODE BEGIN ADC2_Init 2 */
  LL_DMA_ConfigAddresses(
      DMA1, LL_DMA_CHANNEL_2,
      LL_ADC_DMA_GetRegAddr(ADC2, LL_ADC_DMA_REG_REGULAR_DATA),
      (uint32_t)&adc2_data[0], LL_DMA_DIRECTION_PERIPH_TO_MEMORY);
  LL_DMA_SetDataLength(DMA1, LL_DMA_CHANNEL_2, (uint32_t)NUM_TAPS * 3);
  // LL_DMA_EnableIT_TC(DMA1, LL_DMA_CHANNEL_2);
  LL_DMA_EnableChannel(DMA1, LL_DMA_CHANNEL_2);
  /* USER CODE END ADC2_Init 2 */

}

static void MX_ADC3_Init(void)
{

  LL_ADC_InitTypeDef ADC_InitStruct = {0};
  LL_ADC_REG_InitTypeDef ADC_REG_InitStruct = {0};
  LL_ADC_CommonInitTypeDef ADC_CommonInitStruct = {0};

  LL_GPIO_InitTypeDef GPIO_InitStruct = {0};

  LL_RCC_SetADCClockSource(LL_RCC_ADC345_CLKSOURCE_SYSCLK);

  /* Peripheral clock enable */
  LL_AHB2_GRP1_EnableClock(LL_AHB2_GRP1_PERIPH_ADC345);

  LL_AHB2_GRP1_EnableClock(LL_AHB2_GRP1_PERIPH_GPIOB);
  /**ADC3 GPIO Configuration
  PB1   ------> ADC3_IN1
  PB13   ------> ADC3_IN5
  */
  GPIO_InitStruct.Pin = I_AC_3_Pin;
  GPIO_InitStruct.Mode = LL_GPIO_MODE_ANALOG;
  GPIO_InitStruct.Pull = LL_GPIO_PULL_NO;
  LL_GPIO_Init(I_AC_3_GPIO_Port, &GPIO_InitStruct);

  GPIO_InitStruct.Pin = V_AC_3_Pin;
  GPIO_InitStruct.Mode = LL_GPIO_MODE_ANALOG;
  GPIO_InitStruct.Pull = LL_GPIO_PULL_NO;
  LL_GPIO_Init(V_AC_3_GPIO_Port, &GPIO_InitStruct);

  /* ADC3 DMA Init */

  /* ADC3 Init */
  LL_DMA_SetPeriphRequest(DMA1, LL_DMA_CHANNEL_3, LL_DMAMUX_REQ_ADC3);

  LL_DMA_SetDataTransferDirection(DMA1, LL_DMA_CHANNEL_3, LL_DMA_DIRECTION_PERIPH_TO_MEMORY);

  LL_DMA_SetChannelPriorityLevel(DMA1, LL_DMA_CHANNEL_3, LL_DMA_PRIORITY_HIGH);

  LL_DMA_SetMode(DMA1, LL_DMA_CHANNEL_3, LL_DMA_MODE_CIRCULAR);

  LL_DMA_SetPeriphIncMode(DMA1, LL_DMA_CHANNEL_3, LL_DMA_PERIPH_NOINCREMENT);

  LL_DMA_SetMemoryIncMode(DMA1, LL_DMA_CHANNEL_3, LL_DMA_MEMORY_INCREMENT);

  LL_DMA_SetPeriphSize(DMA1, LL_DMA_CHANNEL_3, LL_DMA_PDATAALIGN_WORD);

  LL_DMA_SetMemorySize(DMA1, LL_DMA_CHANNEL_3, LL_DMA_MDATAALIGN_WORD);

  /** Common config
  */
  ADC_InitStruct.Resolution = LL_ADC_RESOLUTION_12B;
  ADC_InitStruct.DataAlignment = LL_ADC_DATA_ALIGN_RIGHT;
  ADC_InitStruct.LowPowerMode = LL_ADC_LP_MODE_NONE;
  LL_ADC_Init(ADC3, &ADC_InitStruct);
  ADC_REG_InitStruct.TriggerSource = LL_ADC_REG_TRIG_EXT_TIM1_TRGO;
  ADC_REG_InitStruct.SequencerLength = LL_ADC_REG_SEQ_SCAN_ENABLE_2RANKS;
  ADC_REG_InitStruct.SequencerDiscont = LL_ADC_REG_SEQ_DISCONT_DISABLE;
  ADC_REG_InitStruct.ContinuousMode = LL_ADC_REG_CONV_SINGLE;
  ADC_REG_InitStruct.DMATransfer = LL_ADC_REG_DMA_TRANSFER_UNLIMITED;
  ADC_REG_InitStruct.Overrun = LL_ADC_REG_OVR_DATA_PRESERVED;
  LL_ADC_REG_Init(ADC3, &ADC_REG_InitStruct);
  LL_ADC_SetGainCompensation(ADC3, 0);
  LL_ADC_SetOverSamplingScope(ADC3, LL_ADC_OVS_DISABLE);
  ADC_CommonInitStruct.CommonClock = LL_ADC_CLOCK_ASYNC_DIV6;
  ADC_CommonInitStruct.Multimode = LL_ADC_MULTI_INDEPENDENT;
  LL_ADC_CommonInit(__LL_ADC_COMMON_INSTANCE(ADC3), &ADC_CommonInitStruct);
  LL_ADC_REG_SetTriggerEdge(ADC3, LL_ADC_REG_TRIG_EXT_RISING);

  /* Disable ADC deep power down (enabled by default after reset state) */
  LL_ADC_DisableDeepPowerDown(ADC3);
  /* Enable ADC internal voltage regulator */
  LL_ADC_EnableInternalRegulator(ADC3);
  /* Delay for ADC internal voltage regulator stabilization. */
  /* Compute number of CPU cycles to wait for, from delay in us. */
  /* Note: Variable divided by 2 to compensate partially */
  /* CPU processing cycles (depends on compilation optimization). */
  /* Note: If system core clock frequency is below 200kHz, wait time */
  /* is only a few CPU processing cycles. */
  uint32_t wait_loop_index;
  wait_loop_index = ((LL_ADC_DELAY_INTERNAL_REGUL_STAB_US * (SystemCoreClock / (100000 * 2))) / 10);
  while(wait_loop_index != 0)
  {
    wait_loop_index--;
  }

  /** Configure Regular Channel
  */
  LL_ADC_REG_SetSequencerRanks(ADC3, LL_ADC_REG_RANK_1, LL_ADC_CHANNEL_1);
  LL_ADC_SetChannelSamplingTime(ADC3, LL_ADC_CHANNEL_1, LL_ADC_SAMPLINGTIME_92CYCLES_5);
  LL_ADC_SetChannelSingleDiff(ADC3, LL_ADC_CHANNEL_1, LL_ADC_SINGLE_ENDED);

  /** Configure Regular Channel
  */
  LL_ADC_REG_SetSequencerRanks(ADC3, LL_ADC_REG_RANK_2, LL_ADC_CHANNEL_5);
  LL_ADC_SetChannelSamplingTime(ADC3, LL_ADC_CHANNEL_5, LL_ADC_SAMPLINGTIME_92CYCLES_5);
  LL_ADC_SetChannelSingleDiff(ADC3, LL_ADC_CHANNEL_5, LL_ADC_SINGLE_ENDED);
  /* USER CODE BEGIN ADC3_Init 2 */
  LL_DMA_ConfigAddresses(
      DMA1, LL_DMA_CHANNEL_3,
      LL_ADC_DMA_GetRegAddr(ADC3, LL_ADC_DMA_REG_REGULAR_DATA),
      (uint32_t)&adc3_data[0], LL_DMA_DIRECTION_PERIPH_TO_MEMORY);
  LL_DMA_SetDataLength(DMA1, LL_DMA_CHANNEL_3, (uint32_t)NUM_TAPS * 2);
  // LL_DMA_EnableIT_TC(DMA1, LL_DMA_CHANNEL_3);
  LL_DMA_EnableChannel(DMA1, LL_DMA_CHANNEL_3);
  /* USER CODE END ADC3_Init 2 */

}

static void MX_FMAC_Init(void)
{

  /* Peripheral clock enable */
  LL_AHB1_GRP1_EnableClock(LL_AHB1_GRP1_PERIPH_FMAC);

  /* USER CODE BEGIN FMAC_Init 1 */

  static int16_t aFilterCoeffB[NUM_TAPS] = {0x0465, 0x145b, 0x2737,
                                            0x2737, 0x145b, 0x0465};

  LL_FMAC_ConfigX1(FMAC, LL_FMAC_WM_0_THRESHOLD_1, NUM_TAPS + 1, NUM_TAPS);
  LL_FMAC_ConfigX2(FMAC, 0, NUM_TAPS);
  LL_FMAC_ConfigY(FMAC, LL_FMAC_WM_0_THRESHOLD_1, NUM_TAPS + NUM_TAPS + 2, 1);
  LL_FMAC_ConfigFunc(FMAC, LL_FMAC_PROCESSING_START, LL_FMAC_FUNC_LOAD_X2,
                     NUM_TAPS, 0, 0);
  int cnt = 0;
  while (cnt < NUM_TAPS) {
    LL_FMAC_WriteData(FMAC, aFilterCoeffB[cnt]);
    cnt++;
  }

  /* USER CODE END FMAC_Init 1 */

  /* nothing to be configured */

}

static void MX_HRTIM1_Init(void)
{

  LL_GPIO_InitTypeDef GPIO_InitStruct = {0};

  /* Peripheral clock enable */
  LL_APB2_GRP1_EnableClock(LL_APB2_GRP1_PERIPH_HRTIM1);

  LL_HRTIM_ConfigDLLCalibration(HRTIM1, LL_HRTIM_DLLCALIBRATION_MODE_CONTINUOUS, LL_HRTIM_DLLCALIBRATION_RATE_3);

  /* Poll for DLL end of calibration */
#if (USE_TIMEOUT == 1)
  uint32_t Timeout = 10; /* Timeout Initialization */
#endif  /*USE_TIMEOUT*/

  while(LL_HRTIM_IsActiveFlag_DLLRDY(HRTIM1) == RESET){
#if (USE_TIMEOUT == 1)
    if (LL_SYSTICK_IsActiveCounterFlag())  /* Check Systick counter flag to decrement the time-out value */
    {
        if(Timeout-- == 0)
        {
          Error_Handler();  /* error management */
        }
    }
#endif  /* USE_TIMEOUT */
  }

  LL_HRTIM_TIM_SetPrescaler(HRTIM1, LL_HRTIM_TIMER_MASTER, LL_HRTIM_PRESCALERRATIO_MUL16);
  LL_HRTIM_TIM_SetCounterMode(HRTIM1, LL_HRTIM_TIMER_MASTER, LL_HRTIM_MODE_CONTINUOUS);
  LL_HRTIM_TIM_SetPeriod(HRTIM1, LL_HRTIM_TIMER_MASTER, 41846);
  LL_HRTIM_TIM_SetRepetition(HRTIM1, LL_HRTIM_TIMER_MASTER, 0x00);
  LL_HRTIM_TIM_DisableHalfMode(HRTIM1, LL_HRTIM_TIMER_MASTER);
  LL_HRTIM_TIM_SetInterleavedMode(HRTIM1, LL_HRTIM_TIMER_MASTER, LL_HRTIM_INTERLEAVED_MODE_DISABLED);
  LL_HRTIM_TIM_DisableStartOnSync(HRTIM1, LL_HRTIM_TIMER_MASTER);
  LL_HRTIM_TIM_DisableResetOnSync(HRTIM1, LL_HRTIM_TIMER_MASTER);
  LL_HRTIM_TIM_SetDACTrig(HRTIM1, LL_HRTIM_TIMER_MASTER, LL_HRTIM_DACTRIG_NONE);
  LL_HRTIM_TIM_DisablePreload(HRTIM1, LL_HRTIM_TIMER_MASTER);
  LL_HRTIM_TIM_SetUpdateGating(HRTIM1, LL_HRTIM_TIMER_MASTER, LL_HRTIM_UPDATEGATING_INDEPENDENT);
  LL_HRTIM_TIM_SetUpdateTrig(HRTIM1, LL_HRTIM_TIMER_MASTER, LL_HRTIM_UPDATETRIG_NONE);
  LL_HRTIM_TIM_SetBurstModeOption(HRTIM1, LL_HRTIM_TIMER_MASTER, LL_HRTIM_BURSTMODE_MAINTAINCLOCK);
  LL_HRTIM_ForceUpdate(HRTIM1, LL_HRTIM_TIMER_MASTER);
  LL_HRTIM_TIM_SetCompare1(HRTIM1, LL_HRTIM_TIMER_MASTER, 0xFFEF);

  /* Poll for DLL end of calibration */
#if (USE_TIMEOUT == 1)
  uint32_t Timeout = 10; /* Timeout Initialization */
#endif  /*USE_TIMEOUT*/

  while(LL_HRTIM_IsActiveFlag_DLLRDY(HRTIM1) == RESET){
#if (USE_TIMEOUT == 1)
    if (LL_SYSTICK_IsActiveCounterFlag())  /* Check Systick counter flag to decrement the time-out value */
    {
        if(Timeout-- == 0)
        {
          Error_Handler();  /* error management */
        }
    }
#endif  /* USE_TIMEOUT */
  }

  LL_HRTIM_TIM_SetPrescaler(HRTIM1, LL_HRTIM_TIMER_A, LL_HRTIM_PRESCALERRATIO_MUL32);
  LL_HRTIM_TIM_SetCounterMode(HRTIM1, LL_HRTIM_TIMER_A, LL_HRTIM_MODE_CONTINUOUS);
  LL_HRTIM_TIM_SetPeriod(HRTIM1, LL_HRTIM_TIMER_A, 41846);
  LL_HRTIM_TIM_SetRepetition(HRTIM1, LL_HRTIM_TIMER_A, 0x00);
  LL_HRTIM_TIM_SetUpdateGating(HRTIM1, LL_HRTIM_TIMER_A, LL_HRTIM_UPDATEGATING_INDEPENDENT);
  LL_HRTIM_TIM_SetCountingMode(HRTIM1, LL_HRTIM_TIMER_A, LL_HRTIM_COUNTING_MODE_UP_DOWN);
  LL_HRTIM_TIM_SetComp1Mode(HRTIM1, LL_HRTIM_TIMER_A, LL_HRTIM_GTCMP1_GREATER);
  LL_HRTIM_TIM_SetRollOverMode(HRTIM1, LL_HRTIM_TIMER_A, LL_HRTIM_ROLLOVER_MODE_BOTH);
  LL_HRTIM_TIM_SetFaultEventRollOverMode(HRTIM1, LL_HRTIM_TIMER_A, LL_HRTIM_ROLLOVER_MODE_BOTH);
  LL_HRTIM_TIM_SetBMRollOverMode(HRTIM1, LL_HRTIM_TIMER_A, LL_HRTIM_ROLLOVER_MODE_BOTH);
  LL_HRTIM_TIM_SetADCRollOverMode(HRTIM1, LL_HRTIM_TIMER_A, LL_HRTIM_ROLLOVER_MODE_BOTH);
  LL_HRTIM_TIM_SetOutputRollOverMode(HRTIM1, LL_HRTIM_TIMER_A, LL_HRTIM_ROLLOVER_MODE_BOTH);
  LL_HRTIM_TIM_SetDACTrig(HRTIM1, LL_HRTIM_TIMER_A, LL_HRTIM_DACTRIG_NONE);
  LL_HRTIM_TIM_DisableHalfMode(HRTIM1, LL_HRTIM_TIMER_A);
  LL_HRTIM_TIM_SetInterleavedMode(HRTIM1, LL_HRTIM_TIMER_A, LL_HRTIM_INTERLEAVED_MODE_DISABLED);
  LL_HRTIM_TIM_DisableStartOnSync(HRTIM1, LL_HRTIM_TIMER_A);
  LL_HRTIM_TIM_DisableResetOnSync(HRTIM1, LL_HRTIM_TIMER_A);
  LL_HRTIM_TIM_EnablePreload(HRTIM1, LL_HRTIM_TIMER_A);
  LL_HRTIM_TIM_SetUpdateTrig(HRTIM1, LL_HRTIM_TIMER_A, LL_HRTIM_UPDATETRIG_NONE|LL_HRTIM_UPDATETRIG_REPETITION);
  LL_HRTIM_TIM_SetResetTrig(HRTIM1, LL_HRTIM_TIMER_A, LL_HRTIM_RESETTRIG_MASTER_CMP1);
  LL_HRTIM_TIM_DisablePushPullMode(HRTIM1, LL_HRTIM_TIMER_A);
  LL_HRTIM_TIM_EnableDeadTime(HRTIM1, LL_HRTIM_TIMER_A);
  LL_HRTIM_TIM_SetBurstModeOption(HRTIM1, LL_HRTIM_TIMER_A, LL_HRTIM_BURSTMODE_MAINTAINCLOCK);
  LL_HRTIM_ForceUpdate(HRTIM1, LL_HRTIM_TIMER_A);
  LL_HRTIM_TIM_DisableResyncUpdate(HRTIM1, LL_HRTIM_TIMER_A);
  LL_HRTIM_TIM_SetCompare1(HRTIM1, LL_HRTIM_TIMER_A, 30000);
  LL_HRTIM_DT_SetPrescaler(HRTIM1, LL_HRTIM_TIMER_A, LL_HRTIM_DT_PRESCALER_MUL8);
  LL_HRTIM_DT_SetRisingValue(HRTIM1, LL_HRTIM_TIMER_A, 320);
  LL_HRTIM_DT_SetRisingSign(HRTIM1, LL_HRTIM_TIMER_A, LL_HRTIM_DT_RISING_POSITIVE);
  LL_HRTIM_DT_SetFallingValue(HRTIM1, LL_HRTIM_TIMER_A, 274);
  LL_HRTIM_DT_SetFallingSign(HRTIM1, LL_HRTIM_TIMER_A, LL_HRTIM_DT_FALLING_POSITIVE);
  LL_HRTIM_OUT_SetPolarity(HRTIM1, LL_HRTIM_OUTPUT_TA1, LL_HRTIM_OUT_POSITIVE_POLARITY);
  LL_HRTIM_OUT_SetOutputSetSrc(HRTIM1, LL_HRTIM_OUTPUT_TA1, LL_HRTIM_OUTPUTSET_TIMCMP1);
  LL_HRTIM_OUT_SetOutputResetSrc(HRTIM1, LL_HRTIM_OUTPUT_TA1, LL_HRTIM_OUTPUTRESET_TIMCMP1);
  LL_HRTIM_OUT_SetIdleMode(HRTIM1, LL_HRTIM_OUTPUT_TA1, LL_HRTIM_OUT_NO_IDLE);
  LL_HRTIM_OUT_SetIdleLevel(HRTIM1, LL_HRTIM_OUTPUT_TA1, LL_HRTIM_OUT_IDLELEVEL_INACTIVE);
  LL_HRTIM_OUT_SetFaultState(HRTIM1, LL_HRTIM_OUTPUT_TA1, LL_HRTIM_OUT_FAULTSTATE_NO_ACTION);
  LL_HRTIM_OUT_SetChopperMode(HRTIM1, LL_HRTIM_OUTPUT_TA1, LL_HRTIM_OUT_CHOPPERMODE_DISABLED);
  LL_HRTIM_OUT_SetPolarity(HRTIM1, LL_HRTIM_OUTPUT_TA2, LL_HRTIM_OUT_POSITIVE_POLARITY);
  LL_HRTIM_OUT_SetOutputSetSrc(HRTIM1, LL_HRTIM_OUTPUT_TA2, LL_HRTIM_OUTPUTSET_TIMCMP1);
  LL_HRTIM_OUT_SetOutputResetSrc(HRTIM1, LL_HRTIM_OUTPUT_TA2, LL_HRTIM_OUTPUTRESET_TIMCMP1);
  LL_HRTIM_OUT_SetIdleMode(HRTIM1, LL_HRTIM_OUTPUT_TA2, LL_HRTIM_OUT_NO_IDLE);
  LL_HRTIM_OUT_SetIdleLevel(HRTIM1, LL_HRTIM_OUTPUT_TA2, LL_HRTIM_OUT_IDLELEVEL_INACTIVE);
  LL_HRTIM_OUT_SetFaultState(HRTIM1, LL_HRTIM_OUTPUT_TA2, LL_HRTIM_OUT_FAULTSTATE_NO_ACTION);
  LL_HRTIM_OUT_SetChopperMode(HRTIM1, LL_HRTIM_OUTPUT_TA2, LL_HRTIM_OUT_CHOPPERMODE_DISABLED);

  /* Poll for DLL end of calibration */
#if (USE_TIMEOUT == 1)
  uint32_t Timeout = 10; /* Timeout Initialization */
#endif  /*USE_TIMEOUT*/

  while(LL_HRTIM_IsActiveFlag_DLLRDY(HRTIM1) == RESET){
#if (USE_TIMEOUT == 1)
    if (LL_SYSTICK_IsActiveCounterFlag())  /* Check Systick counter flag to decrement the time-out value */
    {
        if(Timeout-- == 0)
        {
          Error_Handler();  /* error management */
        }
    }
#endif  /* USE_TIMEOUT */
  }

  LL_HRTIM_TIM_SetPrescaler(HRTIM1, LL_HRTIM_TIMER_B, LL_HRTIM_PRESCALERRATIO_MUL32);
  LL_HRTIM_TIM_SetCounterMode(HRTIM1, LL_HRTIM_TIMER_B, LL_HRTIM_MODE_CONTINUOUS);
  LL_HRTIM_TIM_SetPeriod(HRTIM1, LL_HRTIM_TIMER_B, 41846);
  LL_HRTIM_TIM_SetRepetition(HRTIM1, LL_HRTIM_TIMER_B, 0x00);
  LL_HRTIM_TIM_SetUpdateGating(HRTIM1, LL_HRTIM_TIMER_B, LL_HRTIM_UPDATEGATING_INDEPENDENT);
  LL_HRTIM_TIM_SetCountingMode(HRTIM1, LL_HRTIM_TIMER_B, LL_HRTIM_COUNTING_MODE_UP_DOWN);
  LL_HRTIM_TIM_SetComp1Mode(HRTIM1, LL_HRTIM_TIMER_B, LL_HRTIM_GTCMP1_GREATER);
  LL_HRTIM_TIM_SetRollOverMode(HRTIM1, LL_HRTIM_TIMER_B, LL_HRTIM_ROLLOVER_MODE_BOTH);
  LL_HRTIM_TIM_SetFaultEventRollOverMode(HRTIM1, LL_HRTIM_TIMER_B, LL_HRTIM_ROLLOVER_MODE_BOTH);
  LL_HRTIM_TIM_SetBMRollOverMode(HRTIM1, LL_HRTIM_TIMER_B, LL_HRTIM_ROLLOVER_MODE_BOTH);
  LL_HRTIM_TIM_SetADCRollOverMode(HRTIM1, LL_HRTIM_TIMER_B, LL_HRTIM_ROLLOVER_MODE_BOTH);
  LL_HRTIM_TIM_SetOutputRollOverMode(HRTIM1, LL_HRTIM_TIMER_B, LL_HRTIM_ROLLOVER_MODE_BOTH);
  LL_HRTIM_TIM_SetDACTrig(HRTIM1, LL_HRTIM_TIMER_B, LL_HRTIM_DACTRIG_NONE);
  LL_HRTIM_TIM_DisableHalfMode(HRTIM1, LL_HRTIM_TIMER_B);
  LL_HRTIM_TIM_SetInterleavedMode(HRTIM1, LL_HRTIM_TIMER_B, LL_HRTIM_INTERLEAVED_MODE_DISABLED);
  LL_HRTIM_TIM_DisableStartOnSync(HRTIM1, LL_HRTIM_TIMER_B);
  LL_HRTIM_TIM_DisableResetOnSync(HRTIM1, LL_HRTIM_TIMER_B);
  LL_HRTIM_TIM_EnablePreload(HRTIM1, LL_HRTIM_TIMER_B);
  LL_HRTIM_TIM_SetUpdateTrig(HRTIM1, LL_HRTIM_TIMER_B, LL_HRTIM_UPDATETRIG_MASTER|LL_HRTIM_UPDATETRIG_REPETITION);
  LL_HRTIM_TIM_SetResetTrig(HRTIM1, LL_HRTIM_TIMER_B, LL_HRTIM_RESETTRIG_MASTER_CMP1);
  LL_HRTIM_TIM_DisablePushPullMode(HRTIM1, LL_HRTIM_TIMER_B);
  LL_HRTIM_TIM_EnableDeadTime(HRTIM1, LL_HRTIM_TIMER_B);
  LL_HRTIM_TIM_SetBurstModeOption(HRTIM1, LL_HRTIM_TIMER_B, LL_HRTIM_BURSTMODE_MAINTAINCLOCK);
  LL_HRTIM_ForceUpdate(HRTIM1, LL_HRTIM_TIMER_B);
  LL_HRTIM_TIM_DisableResyncUpdate(HRTIM1, LL_HRTIM_TIMER_B);
  LL_HRTIM_TIM_SetCompare1(HRTIM1, LL_HRTIM_TIMER_B, 10000);
  LL_HRTIM_DT_SetPrescaler(HRTIM1, LL_HRTIM_TIMER_B, LL_HRTIM_DT_PRESCALER_MUL8);
  LL_HRTIM_DT_SetRisingValue(HRTIM1, LL_HRTIM_TIMER_B, 320);
  LL_HRTIM_DT_SetRisingSign(HRTIM1, LL_HRTIM_TIMER_B, LL_HRTIM_DT_RISING_POSITIVE);
  LL_HRTIM_DT_SetFallingValue(HRTIM1, LL_HRTIM_TIMER_B, 274);
  LL_HRTIM_DT_SetFallingSign(HRTIM1, LL_HRTIM_TIMER_B, LL_HRTIM_DT_FALLING_POSITIVE);
  LL_HRTIM_OUT_SetPolarity(HRTIM1, LL_HRTIM_OUTPUT_TB1, LL_HRTIM_OUT_POSITIVE_POLARITY);
  LL_HRTIM_OUT_SetOutputSetSrc(HRTIM1, LL_HRTIM_OUTPUT_TB1, LL_HRTIM_OUTPUTSET_TIMCMP1);
  LL_HRTIM_OUT_SetOutputResetSrc(HRTIM1, LL_HRTIM_OUTPUT_TB1, LL_HRTIM_OUTPUTRESET_TIMCMP1);
  LL_HRTIM_OUT_SetIdleMode(HRTIM1, LL_HRTIM_OUTPUT_TB1, LL_HRTIM_OUT_NO_IDLE);
  LL_HRTIM_OUT_SetIdleLevel(HRTIM1, LL_HRTIM_OUTPUT_TB1, LL_HRTIM_OUT_IDLELEVEL_INACTIVE);
  LL_HRTIM_OUT_SetFaultState(HRTIM1, LL_HRTIM_OUTPUT_TB1, LL_HRTIM_OUT_FAULTSTATE_NO_ACTION);
  LL_HRTIM_OUT_SetChopperMode(HRTIM1, LL_HRTIM_OUTPUT_TB1, LL_HRTIM_OUT_CHOPPERMODE_DISABLED);
  LL_HRTIM_OUT_SetPolarity(HRTIM1, LL_HRTIM_OUTPUT_TB2, LL_HRTIM_OUT_POSITIVE_POLARITY);
  LL_HRTIM_OUT_SetOutputSetSrc(HRTIM1, LL_HRTIM_OUTPUT_TB2, LL_HRTIM_OUTPUTSET_NONE);
  LL_HRTIM_OUT_SetOutputResetSrc(HRTIM1, LL_HRTIM_OUTPUT_TB2, LL_HRTIM_OUTPUTRESET_NONE);
  LL_HRTIM_OUT_SetIdleMode(HRTIM1, LL_HRTIM_OUTPUT_TB2, LL_HRTIM_OUT_NO_IDLE);
  LL_HRTIM_OUT_SetIdleLevel(HRTIM1, LL_HRTIM_OUTPUT_TB2, LL_HRTIM_OUT_IDLELEVEL_INACTIVE);
  LL_HRTIM_OUT_SetFaultState(HRTIM1, LL_HRTIM_OUTPUT_TB2, LL_HRTIM_OUT_FAULTSTATE_NO_ACTION);
  LL_HRTIM_OUT_SetChopperMode(HRTIM1, LL_HRTIM_OUTPUT_TB2, LL_HRTIM_OUT_CHOPPERMODE_DISABLED);

  /* Poll for DLL end of calibration */
#if (USE_TIMEOUT == 1)
  uint32_t Timeout = 10; /* Timeout Initialization */
#endif  /*USE_TIMEOUT*/

  while(LL_HRTIM_IsActiveFlag_DLLRDY(HRTIM1) == RESET){
#if (USE_TIMEOUT == 1)
    if (LL_SYSTICK_IsActiveCounterFlag())  /* Check Systick counter flag to decrement the time-out value */
    {
        if(Timeout-- == 0)
        {
          Error_Handler();  /* error management */
        }
    }
#endif  /* USE_TIMEOUT */
  }

  LL_HRTIM_TIM_SetPrescaler(HRTIM1, LL_HRTIM_TIMER_E, LL_HRTIM_PRESCALERRATIO_MUL32);
  LL_HRTIM_TIM_SetCounterMode(HRTIM1, LL_HRTIM_TIMER_E, LL_HRTIM_MODE_CONTINUOUS);
  LL_HRTIM_TIM_SetPeriod(HRTIM1, LL_HRTIM_TIMER_E, 41846);
  LL_HRTIM_TIM_SetRepetition(HRTIM1, LL_HRTIM_TIMER_E, 0x00);
  LL_HRTIM_TIM_SetUpdateGating(HRTIM1, LL_HRTIM_TIMER_E, LL_HRTIM_UPDATEGATING_INDEPENDENT);
  LL_HRTIM_TIM_SetCountingMode(HRTIM1, LL_HRTIM_TIMER_E, LL_HRTIM_COUNTING_MODE_UP_DOWN);
  LL_HRTIM_TIM_SetComp1Mode(HRTIM1, LL_HRTIM_TIMER_E, LL_HRTIM_GTCMP1_GREATER);
  LL_HRTIM_TIM_SetRollOverMode(HRTIM1, LL_HRTIM_TIMER_E, LL_HRTIM_ROLLOVER_MODE_BOTH);
  LL_HRTIM_TIM_SetFaultEventRollOverMode(HRTIM1, LL_HRTIM_TIMER_E, LL_HRTIM_ROLLOVER_MODE_BOTH);
  LL_HRTIM_TIM_SetBMRollOverMode(HRTIM1, LL_HRTIM_TIMER_E, LL_HRTIM_ROLLOVER_MODE_BOTH);
  LL_HRTIM_TIM_SetADCRollOverMode(HRTIM1, LL_HRTIM_TIMER_E, LL_HRTIM_ROLLOVER_MODE_BOTH);
  LL_HRTIM_TIM_SetOutputRollOverMode(HRTIM1, LL_HRTIM_TIMER_E, LL_HRTIM_ROLLOVER_MODE_BOTH);
  LL_HRTIM_TIM_SetDACTrig(HRTIM1, LL_HRTIM_TIMER_E, LL_HRTIM_DACTRIG_NONE);
  LL_HRTIM_TIM_DisableHalfMode(HRTIM1, LL_HRTIM_TIMER_E);
  LL_HRTIM_TIM_SetInterleavedMode(HRTIM1, LL_HRTIM_TIMER_E, LL_HRTIM_INTERLEAVED_MODE_DISABLED);
  LL_HRTIM_TIM_DisableStartOnSync(HRTIM1, LL_HRTIM_TIMER_E);
  LL_HRTIM_TIM_DisableResetOnSync(HRTIM1, LL_HRTIM_TIMER_E);
  LL_HRTIM_TIM_EnablePreload(HRTIM1, LL_HRTIM_TIMER_E);
  LL_HRTIM_TIM_SetUpdateTrig(HRTIM1, LL_HRTIM_TIMER_E, LL_HRTIM_UPDATETRIG_NONE|LL_HRTIM_UPDATETRIG_REPETITION);
  LL_HRTIM_TIM_SetResetTrig(HRTIM1, LL_HRTIM_TIMER_E, LL_HRTIM_RESETTRIG_MASTER_CMP1);
  LL_HRTIM_TIM_DisablePushPullMode(HRTIM1, LL_HRTIM_TIMER_E);
  LL_HRTIM_TIM_EnableDeadTime(HRTIM1, LL_HRTIM_TIMER_E);
  LL_HRTIM_TIM_SetBurstModeOption(HRTIM1, LL_HRTIM_TIMER_E, LL_HRTIM_BURSTMODE_MAINTAINCLOCK);
  LL_HRTIM_ForceUpdate(HRTIM1, LL_HRTIM_TIMER_E);
  LL_HRTIM_TIM_DisableResyncUpdate(HRTIM1, LL_HRTIM_TIMER_E);
  LL_HRTIM_TIM_SetCompare1(HRTIM1, LL_HRTIM_TIMER_E, 20000);
  LL_HRTIM_DT_SetPrescaler(HRTIM1, LL_HRTIM_TIMER_E, LL_HRTIM_DT_PRESCALER_MUL8);
  LL_HRTIM_DT_SetRisingValue(HRTIM1, LL_HRTIM_TIMER_E, 274);
  LL_HRTIM_DT_SetRisingSign(HRTIM1, LL_HRTIM_TIMER_E, LL_HRTIM_DT_RISING_POSITIVE);
  LL_HRTIM_DT_SetFallingValue(HRTIM1, LL_HRTIM_TIMER_E, 320);
  LL_HRTIM_DT_SetFallingSign(HRTIM1, LL_HRTIM_TIMER_E, LL_HRTIM_DT_FALLING_POSITIVE);
  LL_HRTIM_OUT_SetPolarity(HRTIM1, LL_HRTIM_OUTPUT_TE1, LL_HRTIM_OUT_POSITIVE_POLARITY);
  LL_HRTIM_OUT_SetOutputSetSrc(HRTIM1, LL_HRTIM_OUTPUT_TE1, LL_HRTIM_OUTPUTSET_TIMCMP1);
  LL_HRTIM_OUT_SetOutputResetSrc(HRTIM1, LL_HRTIM_OUTPUT_TE1, LL_HRTIM_OUTPUTRESET_TIMCMP1);
  LL_HRTIM_OUT_SetIdleMode(HRTIM1, LL_HRTIM_OUTPUT_TE1, LL_HRTIM_OUT_NO_IDLE);
  LL_HRTIM_OUT_SetIdleLevel(HRTIM1, LL_HRTIM_OUTPUT_TE1, LL_HRTIM_OUT_IDLELEVEL_INACTIVE);
  LL_HRTIM_OUT_SetFaultState(HRTIM1, LL_HRTIM_OUTPUT_TE1, LL_HRTIM_OUT_FAULTSTATE_NO_ACTION);
  LL_HRTIM_OUT_SetChopperMode(HRTIM1, LL_HRTIM_OUTPUT_TE1, LL_HRTIM_OUT_CHOPPERMODE_DISABLED);
  LL_HRTIM_OUT_SetPolarity(HRTIM1, LL_HRTIM_OUTPUT_TE2, LL_HRTIM_OUT_POSITIVE_POLARITY);
  LL_HRTIM_OUT_SetOutputSetSrc(HRTIM1, LL_HRTIM_OUTPUT_TE2, LL_HRTIM_OUTPUTSET_NONE);
  LL_HRTIM_OUT_SetOutputResetSrc(HRTIM1, LL_HRTIM_OUTPUT_TE2, LL_HRTIM_OUTPUTRESET_NONE);
  LL_HRTIM_OUT_SetIdleMode(HRTIM1, LL_HRTIM_OUTPUT_TE2, LL_HRTIM_OUT_NO_IDLE);
  LL_HRTIM_OUT_SetIdleLevel(HRTIM1, LL_HRTIM_OUTPUT_TE2, LL_HRTIM_OUT_IDLELEVEL_INACTIVE);
  LL_HRTIM_OUT_SetFaultState(HRTIM1, LL_HRTIM_OUTPUT_TE2, LL_HRTIM_OUT_FAULTSTATE_NO_ACTION);
  LL_HRTIM_OUT_SetChopperMode(HRTIM1, LL_HRTIM_OUTPUT_TE2, LL_HRTIM_OUT_CHOPPERMODE_DISABLED);
  LL_AHB2_GRP1_EnableClock(LL_AHB2_GRP1_PERIPH_GPIOC);
  LL_AHB2_GRP1_EnableClock(LL_AHB2_GRP1_PERIPH_GPIOA);
  /**HRTIM1 GPIO Configuration
  PC8   ------> HRTIM1_CHE1
  PC9   ------> HRTIM1_CHE2
  PA8   ------> HRTIM1_CHA1
  PA9   ------> HRTIM1_CHA2
  PA10   ------> HRTIM1_CHB1
  PA11   ------> HRTIM1_CHB2
  */
  GPIO_InitStruct.Pin = L3_UP_Pin;
  GPIO_InitStruct.Mode = LL_GPIO_MODE_ALTERNATE;
  GPIO_InitStruct.Speed = LL_GPIO_SPEED_FREQ_VERY_HIGH;
  GPIO_InitStruct.OutputType = LL_GPIO_OUTPUT_PUSHPULL;
  GPIO_InitStruct.Pull = LL_GPIO_PULL_NO;
  GPIO_InitStruct.Alternate = LL_GPIO_AF_3;
  LL_GPIO_Init(L3_UP_GPIO_Port, &GPIO_InitStruct);

  GPIO_InitStruct.Pin = L3_DW_Pin;
  GPIO_InitStruct.Mode = LL_GPIO_MODE_ALTERNATE;
  GPIO_InitStruct.Speed = LL_GPIO_SPEED_FREQ_VERY_HIGH;
  GPIO_InitStruct.OutputType = LL_GPIO_OUTPUT_PUSHPULL;
  GPIO_InitStruct.Pull = LL_GPIO_PULL_NO;
  GPIO_InitStruct.Alternate = LL_GPIO_AF_3;
  LL_GPIO_Init(L3_DW_GPIO_Port, &GPIO_InitStruct);

  GPIO_InitStruct.Pin = L1_UP_Pin;
  GPIO_InitStruct.Mode = LL_GPIO_MODE_ALTERNATE;
  GPIO_InitStruct.Speed = LL_GPIO_SPEED_FREQ_VERY_HIGH;
  GPIO_InitStruct.OutputType = LL_GPIO_OUTPUT_PUSHPULL;
  GPIO_InitStruct.Pull = LL_GPIO_PULL_NO;
  GPIO_InitStruct.Alternate = LL_GPIO_AF_13;
  LL_GPIO_Init(L1_UP_GPIO_Port, &GPIO_InitStruct);

  GPIO_InitStruct.Pin = L1_DW_Pin;
  GPIO_InitStruct.Mode = LL_GPIO_MODE_ALTERNATE;
  GPIO_InitStruct.Speed = LL_GPIO_SPEED_FREQ_VERY_HIGH;
  GPIO_InitStruct.OutputType = LL_GPIO_OUTPUT_PUSHPULL;
  GPIO_InitStruct.Pull = LL_GPIO_PULL_NO;
  GPIO_InitStruct.Alternate = LL_GPIO_AF_13;
  LL_GPIO_Init(L1_DW_GPIO_Port, &GPIO_InitStruct);

  GPIO_InitStruct.Pin = L2_UP_Pin;
  GPIO_InitStruct.Mode = LL_GPIO_MODE_ALTERNATE;
  GPIO_InitStruct.Speed = LL_GPIO_SPEED_FREQ_VERY_HIGH;
  GPIO_InitStruct.OutputType = LL_GPIO_OUTPUT_PUSHPULL;
  GPIO_InitStruct.Pull = LL_GPIO_PULL_NO;
  GPIO_InitStruct.Alternate = LL_GPIO_AF_13;
  LL_GPIO_Init(L2_UP_GPIO_Port, &GPIO_InitStruct);

  GPIO_InitStruct.Pin = L2_DW_Pin;
  GPIO_InitStruct.Mode = LL_GPIO_MODE_ALTERNATE;
  GPIO_InitStruct.Speed = LL_GPIO_SPEED_FREQ_VERY_HIGH;
  GPIO_InitStruct.OutputType = LL_GPIO_OUTPUT_PUSHPULL;
  GPIO_InitStruct.Pull = LL_GPIO_PULL_NO;
  GPIO_InitStruct.Alternate = LL_GPIO_AF_13;
  LL_GPIO_Init(L2_DW_GPIO_Port, &GPIO_InitStruct);

}

static void MX_TIM1_Init(void)
{

  LL_TIM_InitTypeDef TIM_InitStruct = {0};

  /* Peripheral clock enable */
  LL_APB2_GRP1_EnableClock(LL_APB2_GRP1_PERIPH_TIM1);

  /* TIM1 interrupt Init */
  NVIC_SetPriority(TIM1_UP_TIM16_IRQn, NVIC_EncodePriority(NVIC_GetPriorityGrouping(),0, 0));
  NVIC_EnableIRQ(TIM1_UP_TIM16_IRQn);

  TIM_InitStruct.Prescaler = 0;
  TIM_InitStruct.CounterMode = LL_TIM_COUNTERMODE_UP;
  TIM_InitStruct.Autoreload = 21250;
  TIM_InitStruct.ClockDivision = LL_TIM_CLOCKDIVISION_DIV1;
  TIM_InitStruct.RepetitionCounter = 0;
  LL_TIM_Init(TIM1, &TIM_InitStruct);
  LL_TIM_DisableARRPreload(TIM1);
  LL_TIM_SetClockSource(TIM1, LL_TIM_CLOCKSOURCE_INTERNAL);
  LL_TIM_SetTriggerOutput(TIM1, LL_TIM_TRGO_UPDATE);
  LL_TIM_SetTriggerOutput2(TIM1, LL_TIM_TRGO2_UPDATE);
  LL_TIM_DisableMasterSlaveMode(TIM1);

}

static void MX_TIM2_Init(void)
{

  LL_TIM_InitTypeDef TIM_InitStruct = {0};

  LL_GPIO_InitTypeDef GPIO_InitStruct = {0};

  /* Peripheral clock enable */
  LL_APB1_GRP1_EnableClock(LL_APB1_GRP1_PERIPH_TIM2);

  LL_AHB2_GRP1_EnableClock(LL_AHB2_GRP1_PERIPH_GPIOB);
  LL_AHB2_GRP1_EnableClock(LL_AHB2_GRP1_PERIPH_GPIOA);
  /**TIM2 GPIO Configuration
  PB10   ------> TIM2_CH3
  PB11   ------> TIM2_CH4
  PA15   ------> TIM2_CH1
  */
  GPIO_InitStruct.Pin = IAC_2_PWM_Pin;
  GPIO_InitStruct.Mode = LL_GPIO_MODE_ALTERNATE;
  GPIO_InitStruct.Speed = LL_GPIO_SPEED_FREQ_HIGH;
  GPIO_InitStruct.OutputType = LL_GPIO_OUTPUT_PUSHPULL;
  GPIO_InitStruct.Pull = LL_GPIO_PULL_NO;
  GPIO_InitStruct.Alternate = LL_GPIO_AF_1;
  LL_GPIO_Init(IAC_2_PWM_GPIO_Port, &GPIO_InitStruct);

  GPIO_InitStruct.Pin = IAC_3_PWM_Pin;
  GPIO_InitStruct.Mode = LL_GPIO_MODE_ALTERNATE;
  GPIO_InitStruct.Speed = LL_GPIO_SPEED_FREQ_HIGH;
  GPIO_InitStruct.OutputType = LL_GPIO_OUTPUT_PUSHPULL;
  GPIO_InitStruct.Pull = LL_GPIO_PULL_NO;
  GPIO_InitStruct.Alternate = LL_GPIO_AF_1;
  LL_GPIO_Init(IAC_3_PWM_GPIO_Port, &GPIO_InitStruct);

  GPIO_InitStruct.Pin = IAC_1_PWM_Pin;
  GPIO_InitStruct.Mode = LL_GPIO_MODE_ALTERNATE;
  GPIO_InitStruct.Speed = LL_GPIO_SPEED_FREQ_HIGH;
  GPIO_InitStruct.OutputType = LL_GPIO_OUTPUT_PUSHPULL;
  GPIO_InitStruct.Pull = LL_GPIO_PULL_NO;
  GPIO_InitStruct.Alternate = LL_GPIO_AF_1;
  LL_GPIO_Init(IAC_1_PWM_GPIO_Port, &GPIO_InitStruct);

  /* TIM2 DMA Init */

  /* TIM2_CH1 Init */
  LL_DMA_SetPeriphRequest(DMA1, LL_DMA_CHANNEL_4, LL_DMAMUX_REQ_TIM2_CH1);

  LL_DMA_SetDataTransferDirection(DMA1, LL_DMA_CHANNEL_4, LL_DMA_DIRECTION_PERIPH_TO_MEMORY);

  LL_DMA_SetChannelPriorityLevel(DMA1, LL_DMA_CHANNEL_4, LL_DMA_PRIORITY_VERYHIGH);

  LL_DMA_SetMode(DMA1, LL_DMA_CHANNEL_4, LL_DMA_MODE_CIRCULAR);

  LL_DMA_SetPeriphIncMode(DMA1, LL_DMA_CHANNEL_4, LL_DMA_PERIPH_NOINCREMENT);

  LL_DMA_SetMemoryIncMode(DMA1, LL_DMA_CHANNEL_4, LL_DMA_MEMORY_INCREMENT);

  LL_DMA_SetPeriphSize(DMA1, LL_DMA_CHANNEL_4, LL_DMA_PDATAALIGN_WORD);

  LL_DMA_SetMemorySize(DMA1, LL_DMA_CHANNEL_4, LL_DMA_MDATAALIGN_WORD);

  /* TIM2_CH2 Init */
  LL_DMA_SetPeriphRequest(DMA1, LL_DMA_CHANNEL_5, LL_DMAMUX_REQ_TIM2_CH2);

  LL_DMA_SetDataTransferDirection(DMA1, LL_DMA_CHANNEL_5, LL_DMA_DIRECTION_PERIPH_TO_MEMORY);

  LL_DMA_SetChannelPriorityLevel(DMA1, LL_DMA_CHANNEL_5, LL_DMA_PRIORITY_VERYHIGH);

  LL_DMA_SetMode(DMA1, LL_DMA_CHANNEL_5, LL_DMA_MODE_CIRCULAR);

  LL_DMA_SetPeriphIncMode(DMA1, LL_DMA_CHANNEL_5, LL_DMA_PERIPH_NOINCREMENT);

  LL_DMA_SetMemoryIncMode(DMA1, LL_DMA_CHANNEL_5, LL_DMA_MEMORY_INCREMENT);

  LL_DMA_SetPeriphSize(DMA1, LL_DMA_CHANNEL_5, LL_DMA_PDATAALIGN_WORD);

  LL_DMA_SetMemorySize(DMA1, LL_DMA_CHANNEL_5, LL_DMA_MDATAALIGN_WORD);

  /* TIM2_CH3 Init */
  LL_DMA_SetPeriphRequest(DMA1, LL_DMA_CHANNEL_6, LL_DMAMUX_REQ_TIM2_CH3);

  LL_DMA_SetDataTransferDirection(DMA1, LL_DMA_CHANNEL_6, LL_DMA_DIRECTION_PERIPH_TO_MEMORY);

  LL_DMA_SetChannelPriorityLevel(DMA1, LL_DMA_CHANNEL_6, LL_DMA_PRIORITY_VERYHIGH);

  LL_DMA_SetMode(DMA1, LL_DMA_CHANNEL_6, LL_DMA_MODE_CIRCULAR);

  LL_DMA_SetPeriphIncMode(DMA1, LL_DMA_CHANNEL_6, LL_DMA_PERIPH_NOINCREMENT);

  LL_DMA_SetMemoryIncMode(DMA1, LL_DMA_CHANNEL_6, LL_DMA_MEMORY_INCREMENT);

  LL_DMA_SetPeriphSize(DMA1, LL_DMA_CHANNEL_6, LL_DMA_PDATAALIGN_WORD);

  LL_DMA_SetMemorySize(DMA1, LL_DMA_CHANNEL_6, LL_DMA_MDATAALIGN_WORD);

  /* TIM2_CH4 Init */
  LL_DMA_SetPeriphRequest(DMA1, LL_DMA_CHANNEL_7, LL_DMAMUX_REQ_TIM2_CH4);

  LL_DMA_SetDataTransferDirection(DMA1, LL_DMA_CHANNEL_7, LL_DMA_DIRECTION_PERIPH_TO_MEMORY);

  LL_DMA_SetChannelPriorityLevel(DMA1, LL_DMA_CHANNEL_7, LL_DMA_PRIORITY_VERYHIGH);

  LL_DMA_SetMode(DMA1, LL_DMA_CHANNEL_7, LL_DMA_MODE_CIRCULAR);

  LL_DMA_SetPeriphIncMode(DMA1, LL_DMA_CHANNEL_7, LL_DMA_PERIPH_NOINCREMENT);

  LL_DMA_SetMemoryIncMode(DMA1, LL_DMA_CHANNEL_7, LL_DMA_MEMORY_INCREMENT);

  LL_DMA_SetPeriphSize(DMA1, LL_DMA_CHANNEL_7, LL_DMA_PDATAALIGN_WORD);

  LL_DMA_SetMemorySize(DMA1, LL_DMA_CHANNEL_7, LL_DMA_MDATAALIGN_WORD);

  TIM_InitStruct.Prescaler = 0;
  TIM_InitStruct.CounterMode = LL_TIM_COUNTERMODE_UP;
  TIM_InitStruct.Autoreload = 4294967295;
  TIM_InitStruct.ClockDivision = LL_TIM_CLOCKDIVISION_DIV1;
  LL_TIM_Init(TIM2, &TIM_InitStruct);
  LL_TIM_DisableARRPreload(TIM2);
  LL_TIM_SetClockSource(TIM2, LL_TIM_CLOCKSOURCE_INTERNAL);
  LL_TIM_SetTriggerInput(TIM2, LL_TIM_TS_TI1FP1);
  LL_TIM_SetSlaveMode(TIM2, LL_TIM_SLAVEMODE_RESET);
  LL_TIM_IC_SetFilter(TIM2, LL_TIM_CHANNEL_CH1, LL_TIM_IC_FILTER_FDIV1);
  LL_TIM_IC_SetPolarity(TIM2, LL_TIM_CHANNEL_CH1, LL_TIM_IC_POLARITY_RISING);
  LL_TIM_DisableIT_TRIG(TIM2);
  LL_TIM_DisableDMAReq_TRIG(TIM2);
  LL_TIM_SetTriggerOutput(TIM2, LL_TIM_TRGO_RESET);
  LL_TIM_DisableMasterSlaveMode(TIM2);
  LL_TIM_IC_SetActiveInput(TIM2, LL_TIM_CHANNEL_CH1, LL_TIM_ACTIVEINPUT_DIRECTTI);
  LL_TIM_IC_SetPrescaler(TIM2, LL_TIM_CHANNEL_CH1, LL_TIM_ICPSC_DIV1);
  LL_TIM_IC_SetFilter(TIM2, LL_TIM_CHANNEL_CH1, LL_TIM_IC_FILTER_FDIV16_N5);
  LL_TIM_IC_SetActiveInput(TIM2, LL_TIM_CHANNEL_CH2, LL_TIM_ACTIVEINPUT_INDIRECTTI);
  LL_TIM_IC_SetPrescaler(TIM2, LL_TIM_CHANNEL_CH2, LL_TIM_ICPSC_DIV1);
  LL_TIM_IC_SetFilter(TIM2, LL_TIM_CHANNEL_CH2, LL_TIM_IC_FILTER_FDIV1);
  LL_TIM_IC_SetPolarity(TIM2, LL_TIM_CHANNEL_CH2, LL_TIM_IC_POLARITY_FALLING);
  LL_TIM_IC_SetActiveInput(TIM2, LL_TIM_CHANNEL_CH3, LL_TIM_ACTIVEINPUT_DIRECTTI);
  LL_TIM_IC_SetPrescaler(TIM2, LL_TIM_CHANNEL_CH3, LL_TIM_ICPSC_DIV1);
  LL_TIM_IC_SetFilter(TIM2, LL_TIM_CHANNEL_CH3, LL_TIM_IC_FILTER_FDIV16_N5);
  LL_TIM_IC_SetPolarity(TIM2, LL_TIM_CHANNEL_CH3, LL_TIM_IC_POLARITY_FALLING);
  LL_TIM_IC_SetActiveInput(TIM2, LL_TIM_CHANNEL_CH4, LL_TIM_ACTIVEINPUT_DIRECTTI);
  LL_TIM_IC_SetPrescaler(TIM2, LL_TIM_CHANNEL_CH4, LL_TIM_ICPSC_DIV1);
  LL_TIM_IC_SetFilter(TIM2, LL_TIM_CHANNEL_CH4, LL_TIM_IC_FILTER_FDIV16_N5);
  LL_TIM_IC_SetPolarity(TIM2, LL_TIM_CHANNEL_CH4, LL_TIM_IC_POLARITY_FALLING);
  /* USER CODE BEGIN TIM2_Init 2 */
  LL_DMA_SetDataLength(DMA1, LL_DMA_CHANNEL_4, 1);
  LL_DMA_ConfigAddresses(
      DMA1, LL_DMA_CHANNEL_4, (uint32_t)&TIM2->CCR1, (uint32_t)&i_ac[0],
      LL_DMA_GetDataTransferDirection(DMA2, LL_DMA_CHANNEL_4));
  LL_DMA_EnableChannel(DMA1, LL_DMA_CHANNEL_4);

  /*CH2 */
  LL_DMA_SetDataLength(DMA1, LL_DMA_CHANNEL_5, 1);
  LL_DMA_ConfigAddresses(
      DMA1, LL_DMA_CHANNEL_5, (uint32_t)&TIM2->CCR2, (uint32_t)&i_ac[1],
      LL_DMA_GetDataTransferDirection(DMA2, LL_DMA_CHANNEL_5));
  LL_DMA_EnableChannel(DMA1, LL_DMA_CHANNEL_5);
  /*CH3 */
  LL_DMA_SetDataLength(DMA1, LL_DMA_CHANNEL_6, 1);
  LL_DMA_ConfigAddresses(
      DMA1, LL_DMA_CHANNEL_6, (uint32_t)&TIM2->CCR3, (uint32_t)&i_ac[2],
      LL_DMA_GetDataTransferDirection(DMA2, LL_DMA_CHANNEL_6));
  LL_DMA_EnableChannel(DMA1, LL_DMA_CHANNEL_6);
  /*CH4 */
  LL_DMA_SetDataLength(DMA1, LL_DMA_CHANNEL_7, 1);
  LL_DMA_ConfigAddresses(
      DMA1, LL_DMA_CHANNEL_7, (uint32_t)&TIM2->CCR4, (uint32_t)&i_ac[3],
      LL_DMA_GetDataTransferDirection(DMA2, LL_DMA_CHANNEL_7));
  LL_DMA_EnableChannel(DMA1, LL_DMA_CHANNEL_7);

  LL_TIM_EnableDMAReq_CC1(TIM2);
  LL_TIM_EnableDMAReq_CC2(TIM2);
  LL_TIM_EnableDMAReq_CC3(TIM2);
  LL_TIM_EnableDMAReq_CC4(TIM2);
  /* USER CODE END TIM2_Init 2 */

}

static void MX_DMA_Init(void)
{

  /* Init with LL driver */
  /* DMA controller clock enable */
  LL_AHB1_GRP1_EnableClock(LL_AHB1_GRP1_PERIPH_DMAMUX1);
  LL_AHB1_GRP1_EnableClock(LL_AHB1_GRP1_PERIPH_DMA1);

  /* DMA interrupt init */
  /* DMA1_Channel1_IRQn interrupt configuration */
  NVIC_SetPriority(DMA1_Channel1_IRQn, NVIC_EncodePriority(NVIC_GetPriorityGrouping(),0, 0));
  NVIC_EnableIRQ(DMA1_Channel1_IRQn);
  /* DMA1_Channel2_IRQn interrupt configuration */
  NVIC_SetPriority(DMA1_Channel2_IRQn, NVIC_EncodePriority(NVIC_GetPriorityGrouping(),0, 0));
  NVIC_EnableIRQ(DMA1_Channel2_IRQn);
  /* DMA1_Channel3_IRQn interrupt configuration */
  NVIC_SetPriority(DMA1_Channel3_IRQn, NVIC_EncodePriority(NVIC_GetPriorityGrouping(),0, 0));
  NVIC_EnableIRQ(DMA1_Channel3_IRQn);
  /* DMA1_Channel4_IRQn interrupt configuration */
  NVIC_SetPriority(DMA1_Channel4_IRQn, NVIC_EncodePriority(NVIC_GetPriorityGrouping(),0, 0));
  NVIC_EnableIRQ(DMA1_Channel4_IRQn);
  /* DMA1_Channel5_IRQn interrupt configuration */
  NVIC_SetPriority(DMA1_Channel5_IRQn, NVIC_EncodePriority(NVIC_GetPriorityGrouping(),0, 0));
  NVIC_EnableIRQ(DMA1_Channel5_IRQn);
  /* DMA1_Channel6_IRQn interrupt configuration */
  NVIC_SetPriority(DMA1_Channel6_IRQn, NVIC_EncodePriority(NVIC_GetPriorityGrouping(),0, 0));
  NVIC_EnableIRQ(DMA1_Channel6_IRQn);
  /* DMA1_Channel7_IRQn interrupt configuration */
  NVIC_SetPriority(DMA1_Channel7_IRQn, NVIC_EncodePriority(NVIC_GetPriorityGrouping(),0, 0));
  NVIC_EnableIRQ(DMA1_Channel7_IRQn);

}

static void MX_GPIO_Init(void)
{
  LL_GPIO_InitTypeDef GPIO_InitStruct = {0};

  /* GPIO Ports Clock Enable */
  LL_AHB2_GRP1_EnableClock(LL_AHB2_GRP1_PERIPH_GPIOC);
  LL_AHB2_GRP1_EnableClock(LL_AHB2_GRP1_PERIPH_GPIOF);
  LL_AHB2_GRP1_EnableClock(LL_AHB2_GRP1_PERIPH_GPIOA);
  LL_AHB2_GRP1_EnableClock(LL_AHB2_GRP1_PERIPH_GPIOB);

  /**/
  LL_GPIO_ResetOutputPin(AUX_GPIO_GPIO_Port, AUX_GPIO_Pin);

  /**/
  LL_GPIO_ResetOutputPin(EN_PFC_GPIO_Port, EN_PFC_Pin);

  /**/
  GPIO_InitStruct.Pin = AUX_GPIO_Pin;
  GPIO_InitStruct.Mode = LL_GPIO_MODE_OUTPUT;
  GPIO_InitStruct.Speed = LL_GPIO_SPEED_FREQ_VERY_HIGH;
  GPIO_InitStruct.OutputType = LL_GPIO_OUTPUT_PUSHPULL;
  GPIO_InitStruct.Pull = LL_GPIO_PULL_NO;
  LL_GPIO_Init(AUX_GPIO_GPIO_Port, &GPIO_InitStruct);

  /**/
  GPIO_InitStruct.Pin = EN_PFC_Pin;
  GPIO_InitStruct.Mode = LL_GPIO_MODE_OUTPUT;
  GPIO_InitStruct.Speed = LL_GPIO_SPEED_FREQ_LOW;
  GPIO_InitStruct.OutputType = LL_GPIO_OUTPUT_PUSHPULL;
  GPIO_InitStruct.Pull = LL_GPIO_PULL_NO;
  LL_GPIO_Init(EN_PFC_GPIO_Port, &GPIO_InitStruct);

}

void Error_Handler(void)
{
  __disable_irq();
  while (1) {
  }
}

#ifdef  USE_FULL_ASSERT
/**
  * @brief  Reports the name of the source file and the source line number
  *         where the assert_param error has occurred.
  * @param  file: pointer to the source file name
  * @param  line: assert_param error line source number
  * @retval None
  */
void assert_failed(uint8_t *file, uint32_t line)
{
  /* USER CODE BEGIN 6 */
  /* User can add his own implementation to report the file name and line
     number, ex: printf("Wrong parameters value: file %s on line %d\r\n", file,
     line) */
  /* USER CODE END 6 */
}
#endif /* USE_FULL_ASSERT */
